VERSION ""

NS_ :

BS_:

BU_: FUSION IVI HMI Telltale

BO_ 535 FD_BCM2: 24 FUSION
 SG_ AmbLightBrightness1 : 190|7@0+ (1,0) [0|127] "" Vector__XXX
 SG_ AmbLightBrightness2 : 182|7@0+ (1,0) [0|127] "" Vector__XXX
 SG_ AmbLightBrightness3 : 174|7@0+ (1,0) [0|127] "" Vector__XXX
 SG_ AmbLightColor1 : 165|6@0+ (1,0) [0|63] "" Vector__XXX
 SG_ AmbLightColor2 : 157|6@0+ (1,0) [0|63] "" Vector__XXX
 SG_ AmbLightColor3 : 149|6@0+ (1,0) [0|63] "" Vector__XXX
 SG_ User1AmbLightColor : 141|6@0+ (1,0) [0|63] "" IVI
 SG_ User2AmbLightColor : 133|6@0+ (1,0) [0|63] "" IVI
 SG_ User3AmbLightColor : 125|6@0+ (1,0) [0|63] "" IVI
 SG_ User4AmbLightColor : 117|6@0+ (1,0) [0|63] "" IVI
 SG_ User5AmbLightColor : 109|6@0+ (1,0) [0|63] "" IVI
 SG_ User6AmbLightColor : 101|6@0+ (1,0) [0|63] "" IVI
 SG_ User1IPAmbLightBrightness : 94|7@0+ (1,0) [0|127] "" IVI
 SG_ User2IPAmbLightBrightness : 86|7@0+ (1,0) [0|127] "" IVI
 SG_ User3IPAmbLightBrightness : 78|7@0+ (1,0) [0|127] "" IVI
 SG_ User4IPAmbLightBrightness : 70|7@0+ (1,0) [0|127] "" IVI
 SG_ User5IPAmbLightBrightness : 62|7@0+ (1,0) [0|127] "" IVI
 SG_ User6IPAmbLightBrightness : 54|7@0+ (1,0) [0|127] "" IVI
 SG_ User1DrAmbLightBrightness : 46|7@0+ (1,0) [0|127] "" IVI
 SG_ User2DrAmbLightBrightness : 38|7@0+ (1,0) [0|127] "" IVI
 SG_ User3DrAmbLightBrightness : 30|7@0+ (1,0) [0|127] "" IVI
 SG_ LampPwr : 31|1@0+ (1,0) [0|1] "" Vector__XXX
 SG_ User4DrAmbLightBrightness : 22|7@0+ (1,0) [0|127] "" IVI
 SG_ AmbLightBreath1 : 23|1@0+ (1,0) [0|1] "" Vector__XXX
 SG_ User5DrAmbLightBrightness : 14|7@0+ (1,0) [0|127] "" IVI
 SG_ AmbLightBreath2 : 15|1@0+ (1,0) [0|1] "" Vector__XXX
 SG_ User6DrAmbLightBrightness : 6|7@0+ (1,0) [0|127] "" IVI
 SG_ AmbLightBreath3 : 7|1@0+ (1,0) [0|1] "" Vector__XXX

BO_ 547 GW_ZoneDR6: 24 FUSION
 SG_ FrntPTCBusLineHiV : 177|10@0+ (1,0) [0|1023] "V" Vector__XXX
 SG_ FrntPTCRiBusLineC : 175|8@0+ (0.1,0) [0|25.5] "A" Vector__XXX
 SG_ FrntPTCLeBusLineC : 167|8@0+ (0.1,0) [0|25.5] "A" Vector__XXX
 SG_ FrntPTCRearRiCoreT : 159|8@0+ (1,-40) [-40|215] "Deg^C" Vector__XXX
 SG_ FrntPTCRearRiActHeatPwr : 151|8@0+ (25,0) [0|6375] "W" IVI
 SG_ FrntPTCRearLeCoreT : 143|8@0+ (1,-40) [-40|215] "Deg^C" Vector__XXX
 SG_ FrntPTCRearLeActHeatPwr : 135|8@0+ (25,0) [0|6375] "W" IVI
 SG_ FrntPTCRearRiBusLineC : 127|8@0+ (0.1,0) [0|25.5] "A" Vector__XXX
 SG_ FrntPTCPCBT : 119|8@0+ (1,-40) [-40|215] "Deg^C" Vector__XXX
 SG_ FrntPTCRiIGBTT : 111|8@0+ (1,-40) [-40|215] "Deg^C" Vector__XXX
 SG_ FrntPTCLeIGBTT : 103|8@0+ (1,-40) [-40|215] "Deg^C" Vector__XXX
 SG_ FrntPTCRiActHeatPwr : 95|8@0+ (25,0) [0|6375] "W" IVI
 SG_ FrntPTCLeActHeatPwr : 87|8@0+ (25,0) [0|6375] "W" IVI
 SG_ FrntPTCRiCoreT : 79|8@0+ (1,-40) [-40|215] "Deg^C" Vector__XXX
 SG_ FrntPTCLeCoreT : 71|8@0+ (1,-40) [-40|215] "Deg^C" Vector__XXX
 SG_ FrntPTCRearLeBusLineC : 63|8@0+ (0.1,0) [0|25.5] "A" Vector__XXX
 SG_ FrntPTCRearLeIGBTShoCFlt : 50|1@0+ (1,0) [0|1] "" Vector__XXX
 SG_ FrntPTCRearRiIGBTShoCFlt : 51|1@0+ (1,0) [0|1] "" Vector__XXX
 SG_ FrntPTCRearRiOpentCircFlt : 52|1@0+ (1,0) [0|1] "" Vector__XXX
 SG_ FrntPTCRearRiOverAFlt : 53|1@0+ (1,0) [0|1] "" Vector__XXX
 SG_ FrntPTCRearLeCoreTSnsrFlt : 54|1@0+ (1,0) [0|1] "" Vector__XXX
 SG_ FrntPTCRearRiCoreTSnsrFlt : 55|1@0+ (1,0) [0|1] "" Vector__XXX
 SG_ FrntPTCRearLeCoreOverTFlt : 40|1@0+ (1,0) [0|1] "" Vector__XXX
 SG_ FrntPTCRearRiCoreOverTFlt : 41|1@0+ (1,0) [0|1] "" Vector__XXX
 SG_ FrntPTCRearLeOpentCircFlt : 42|1@0+ (1,0) [0|1] "" Vector__XXX
 SG_ FrntPTCRearLeOverAFlt : 43|1@0+ (1,0) [0|1] "" Vector__XXX
 SG_ FrntPTCSupplierCod : 47|4@0+ (1,0) [0|15] "" Vector__XXX
 SG_ FrntPTCHWVers : 39|8@0+ (1,0) [0|255] "" Vector__XXX
 SG_ FrntPTCSWVers : 31|8@0+ (1,0) [0|255] "" Vector__XXX
 SG_ FrntPTCRiIGBTOverTFlt : 16|1@0+ (1,0) [0|1] "" Vector__XXX
 SG_ FrntPTCLeIGBTOverTFlt : 17|1@0+ (1,0) [0|1] "" Vector__XXX
 SG_ FrntPTCRiIGBTTSnsrFlt : 18|1@0+ (1,0) [0|1] "" Vector__XXX
 SG_ FrntPTCLeIGBTTSnsrFlt : 19|1@0+ (1,0) [0|1] "" Vector__XXX
 SG_ FrntPTCComFlt : 20|1@0+ (1,0) [0|1] "" Vector__XXX
 SG_ FrntPTCPCBOverTFlt : 21|1@0+ (1,0) [0|1] "" Vector__XXX
 SG_ FrntPTCPCBTSnsrFlt : 22|1@0+ (1,0) [0|1] "" Vector__XXX
 SG_ FrntPTCRiOpentCircFlt : 23|1@0+ (1,0) [0|1] "" Vector__XXX
 SG_ FrntPTCLeOpentCircFlt : 8|1@0+ (1,0) [0|1] "" Vector__XXX
 SG_ FrntPTCRiIGBTShoCircFlt : 9|1@0+ (1,0) [0|1] "" Vector__XXX
 SG_ FrntPTCLeIGBTShoCircFlt : 10|1@0+ (1,0) [0|1] "" Vector__XXX
 SG_ FrntPTCRiCoreOverTFlt : 11|1@0+ (1,0) [0|1] "" Vector__XXX
 SG_ FrntPTCLeCoreOverTFlt : 12|1@0+ (1,0) [0|1] "" Vector__XXX
 SG_ FrntPTCRiCoreTSnsrFlt : 13|1@0+ (1,0) [0|1] "" Vector__XXX
 SG_ FrntPTCLeCoreTSnsrFlt : 14|1@0+ (1,0) [0|1] "" Vector__XXX
 SG_ FrntPTCRiOverAFlt : 15|1@0+ (1,0) [0|1] "" Vector__XXX
 SG_ FrntPTCLeOverAFlt : 0|1@0+ (1,0) [0|1] "" Vector__XXX
 SG_ FrntPTCHVOverUFlt : 1|1@0+ (1,0) [0|1] "" Vector__XXX
 SG_ FrntPTCHVUnderUFlt : 2|1@0+ (1,0) [0|1] "" Vector__XXX
 SG_ FrntPTCLVOverUFlt : 3|1@0+ (1,0) [0|1] "" Vector__XXX
 SG_ FrntPTCLVUnderUFlt : 4|1@0+ (1,0) [0|1] "" Vector__XXX
 SG_ FrntPTCFltSt : 6|2@0+ (1,0) [0|3] "" Vector__XXX
 SG_ FrntPTCSts : 7|1@0+ (1,0) [0|1] "" Vector__XXX

BO_ 550 GW_ZoneDR1: 16 FUSION
 SG_ CSW_SW_version : 87|16@0+ (0.01,0) [0|99.99] "" Vector__XXX
 SG_ CSW_HW_version : 71|16@0+ (0.01,0) [0|99.99] "" Vector__XXX
 SG_ DrLockSta : 56|1@0+ (1,0) [0|1] "" Vector__XXX
 SG_ PsLockSta : 57|1@0+ (1,0) [0|1] "" Vector__XXX
 SG_ RLLockSta : 58|1@0+ (1,0) [0|1] "" Vector__XXX
 SG_ RRLockSta : 59|1@0+ (1,0) [0|1] "" Vector__XXX
 SG_ AllLockSta : 60|1@0+ (1,0) [0|1] "" Vector__XXX
 SG_ MIRROR_FOLD_SW : 61|1@0+ (1,0) [0|1] "" Vector__XXX
 SG_ RWiperAS : 62|1@0+ (1,0) [0|1] "" Vector__XXX
 SG_ RWiperProtection : 63|1@0+ (1,0) [0|1] "" Vector__XXX
 SG_ Wip_Speed : 49|2@0+ (1,0) [0|3] "" Vector__XXX
 SG_ CSW_RWipIntSw_Sta : 51|2@0+ (1,0) [0|3] "" Vector__XXX
 SG_ CSW_DimSw : 52|1@0+ (1,0) [0|1] "" IVI
 SG_ BrakeLampFail : 53|1@0+ (1,0) [0|1] "" Vector__XXX
 SG_ CSW_PassSW_Sta : 54|1@0+ (1,0) [0|1] "" Vector__XXX
 SG_ RLS_Exist : 55|1@0+ (1,0) [0|1] "" Vector__XXX
 SG_ RLTurnLampC : 47|8@0+ (10,0) [0|2550] "mA" Vector__XXX
 SG_ RRTurnLampC : 39|8@0+ (10,0) [0|2550] "mA" Vector__XXX
 SG_ CSW_FWasSw_Sta : 25|2@0+ (1,0) [0|3] "" Vector__XXX
 SG_ CSW_RWasSW_Sta : 27|2@0+ (1,0) [0|3] "" Vector__XXX
 SG_ CSW_TurnSw_Sta : 29|2@0+ (1,0) [0|3] "" IVI
 SG_ HornSW : 30|1@0+ (1,0) [0|1] "" Vector__XXX
 SG_ CSW_FWipSw_Sta : 18|3@0+ (1,0) [0|7] "" IVI
 SG_ RLS_RainSnrWiperCmd : 22|3@0+ (1,0) [0|7] "" Vector__XXX
 SG_ RLS_Lamp_Sta : 23|1@0+ (1,0) [0|1] "" IVI
 SG_ WiperSWPos : 15|8@0+ (1,0) [0|255] "" Vector__XXX
 SG_ CSW_resp_error : 2|1@0+ (1,0) [0|1] "" Vector__XXX
 SG_ AutoLightSW : 3|1@0+ (1,0) [0|1] "" Vector__XXX
 SG_ WiperZeroPosSW : 4|1@0+ (1,0) [0|1] "" Vector__XXX
 SG_ RLS_RainSnrErr : 5|1@0+ (1,0) [0|1] "" Vector__XXX
 SG_ RLS_LightSnrErr : 6|1@0+ (1,0) [0|1] "" Vector__XXX
 SG_ RLS_LIN_Resp_Err : 7|1@0+ (1,0) [0|1] "" Vector__XXX

BO_ 552 GW_ZoneFR1: 20 FUSION
 SG_ CCV4_MoveEnable : 152|1@0+ (1,0) [0|1] "" Vector__XXX
 SG_ CCV4_ReqMovePos : 153|1@0+ (1,0) [0|1] "" Vector__XXX
 SG_ EWP1_Default_Operation_EWP_Rq : 154|1@0+ (1,0) [0|1] "" Vector__XXX
 SG_ EWP3_Default_Operation_EWP_Rq : 155|1@0+ (1,0) [0|1] "" Vector__XXX
 SG_ BDC_1_MoveEnable : 156|1@0+ (1,0) [0|1] "" Vector__XXX
 SG_ EWP2_Default_Operation_EWP_Rq : 157|1@0+ (1,0) [0|1] "" Vector__XXX
 SG_ EXV_Cmd_Move_Enbl : 158|1@0+ (1,0) [0|1] "" Vector__XXX
 SG_ EXV2_Cmd_Move_Enbl : 159|1@0+ (1,0) [0|1] "" Vector__XXX
 SG_ EXV2_Cmd_Init_Rq : 146|3@0+ (1,0) [0|1] "" Vector__XXX
 SG_ EXV_Cmd_Init_Rq : 149|3@0+ (1,0) [0|1] "" Vector__XXX
 SG_ EWP1_RPM_Target_EWP_Rq : 143|8@0+ (1,0) [0|254] "" Vector__XXX
 SG_ EWP3_RPM_Target_EWP_Rq : 135|8@0+ (1,0) [0|254] "" Vector__XXX
 SG_ BDC_1_ReqMovePos : 127|8@0+ (0.392,0) [0|99.96] "" Vector__XXX
 SG_ EWP2_RPM_Target_EWP_Rq : 119|8@0+ (1,0) [0|254] "" Vector__XXX
 SG_ EXV_Cmd_Set_Rq : 103|16@0+ (1,0) [0|576] "" Vector__XXX
 SG_ EXV2_Cmd_Set_Rq : 87|16@0+ (1,0) [0|576] "" Vector__XXX
 SG_ FWiperAS : 56|1@0+ (1,0) [0|1] "" Vector__XXX
 SG_ FWiperProtection : 57|1@0+ (1,0) [0|1] "" Vector__XXX
 SG_ ChargeInletLockSta : 58|1@0+ (1,0) [0|1] "" IVI
 SG_ FLTurnLampC : 55|8@0+ (10,0) [0|2550] "mA" Vector__XXX
 SG_ FRTurnLampC : 47|8@0+ (10,0) [0|2550] "mA" Vector__XXX
 SG_ AGS_Position_Request : 31|8@0+ (1,0) [0|255] "" Vector__XXX
 SG_ AGS_Calibration_Enabled : 22|1@0+ (1,0) [0|1] "" Vector__XXX
 SG_ AGS_LINResponse_Error : 23|1@0+ (1,0) [0|1] "" Vector__XXX
 SG_ AGS_Actuator_Blocked : 8|1@0+ (1,0) [0|1] "" Vector__XXX
 SG_ AGS_Actuator_Fault : 9|1@0+ (1,0) [0|1] "" Vector__XXX
 SG_ AGS_Calibration_Active : 10|1@0+ (1,0) [0|1] "" Vector__XXX
 SG_ AGS_Calibration_Indicated : 11|1@0+ (1,0) [0|1] "" Vector__XXX
 SG_ AGS_Electrical_Error : 12|1@0+ (1,0) [0|1] "" Vector__XXX
 SG_ AGS_Sensor_Error : 13|1@0+ (1,0) [0|1] "" Vector__XXX
 SG_ AGS_Temperature_Error : 14|1@0+ (1,0) [0|1] "" Vector__XXX
 SG_ AGS_Low_Voltage_Error : 15|1@0+ (1,0) [0|1] "" Vector__XXX
 SG_ AGS_Actual_Position : 7|8@0+ (1,0) [0|240] "" IVI

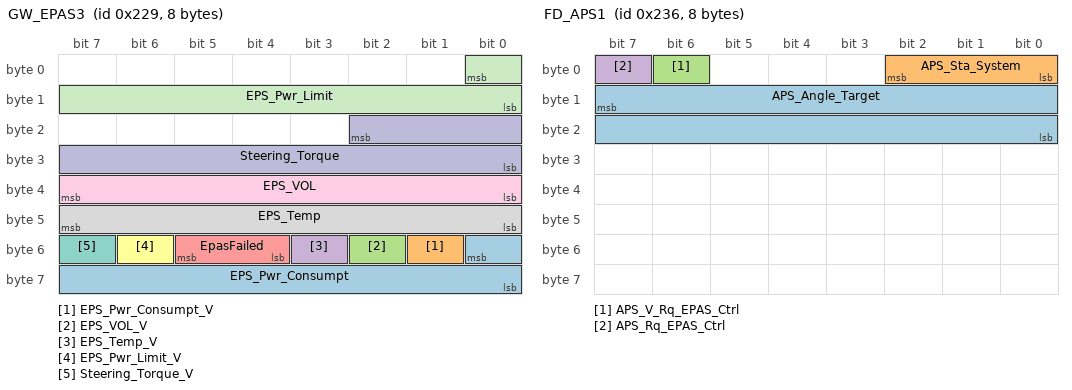
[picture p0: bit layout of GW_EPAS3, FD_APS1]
BO_ 553 GW_EPAS3: 8 FUSION
 SG_ EPS_Pwr_Consumpt : 48|9@0+ (0.5,0) [0|135] "A" Vector__XXX
 SG_ EPS_Pwr_Consumpt_V : 49|1@0+ (1,0) [0|1] "" Vector__XXX
 SG_ EPS_VOL_V : 50|1@0+ (1,0) [0|1] "" Vector__XXX
 SG_ EPS_Temp_V : 51|1@0+ (1,0) [0|1] "" Vector__XXX
 SG_ EpasFailed : 53|2@0+ (1,0) [0|2] "" IVI,Telltale
 SG_ EPS_Pwr_Limit_V : 54|1@0+ (1,0) [0|1] "" Vector__XXX
 SG_ Steering_Torque_V : 55|1@0+ (1,0) [0|1] "" Vector__XXX
 SG_ EPS_Temp : 47|8@0+ (1,-100) [-100|155] "Deg^C" Vector__XXX
 SG_ EPS_VOL : 39|8@0+ (0.1,0) [0|25.5] "V" Vector__XXX
 SG_ Steering_Torque : 18|11@0+ (0.01,-10) [-10|10] "Nm" Vector__XXX
 SG_ EPS_Pwr_Limit : 0|9@0+ (0.5,0) [0|135] "A" Vector__XXX

BO_ 566 FD_APS1: 8 FUSION
 SG_ APS_Angle_Target : 15|16@0+ (0.1,-900) [-900|900] "Deg" Vector__XXX
 SG_ APS_Sta_System : 2|3@0+ (1,0) [0|7] "" IVI
 SG_ APS_V_Rq_EPAS_Ctrl : 6|1@0+ (1,0) [0|1] "" Vector__XXX
 SG_ APS_Rq_EPAS_Ctrl : 7|1@0+ (1,0) [0|1] "" Vector__XXX

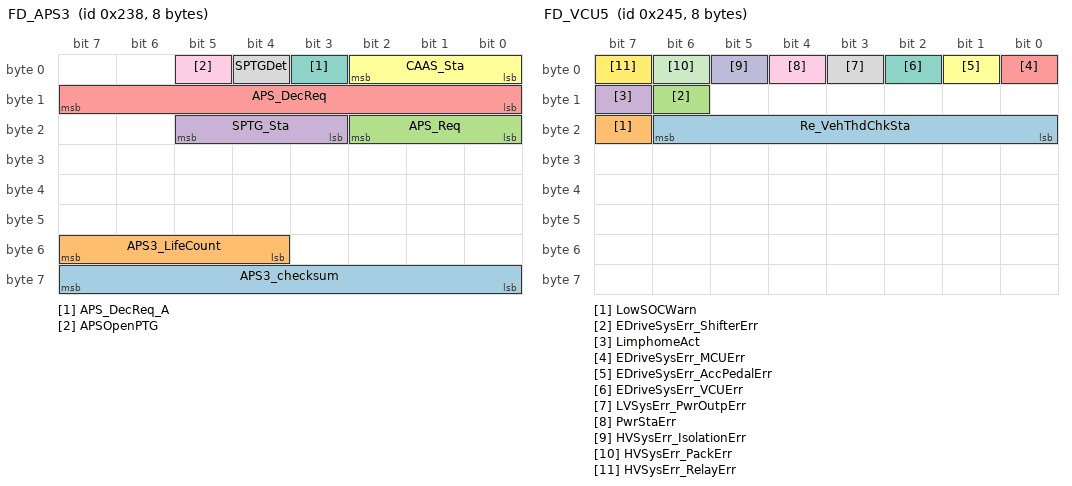
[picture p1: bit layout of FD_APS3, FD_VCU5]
BO_ 568 FD_APS3: 8 FUSION
 SG_ APS3_checksum : 63|8@0+ (1,0) [0|255] "" Vector__XXX
 SG_ APS3_LifeCount : 55|4@0+ (1,0) [0|15] "" Vector__XXX
 SG_ APS_Req : 18|3@0+ (1,0) [0|7] "" Vector__XXX
 SG_ SPTG_Sta : 21|3@0+ (1,0) [0|7] "" Vector__XXX
 SG_ APS_DecReq : 15|8@0+ (0.1,0) [0|25.4] "m/s^2" Vector__XXX
 SG_ CAAS_Sta : 2|3@0+ (1,0) [0|7] "" IVI
 SG_ APS_DecReq_A : 3|1@0+ (1,0) [0|1] "" Vector__XXX
 SG_ SPTGDet : 4|1@0+ (1,0) [0|1] "" Vector__XXX
 SG_ APSOpenPTG : 5|1@0+ (1,0) [0|1] "" Vector__XXX

BO_ 570 GW_FCM4: 8 FUSION
 SG_ FCM4_Checksum : 63|8@0+ (1,0) [0|255] "" IVI
 SG_ ADAS_SLIF_SpdLim : 52|5@0+ (1,0) [0|31] "" IVI
 SG_ Target_Type : 40|4@0+ (1,0) [0|15] "" IVI
 SG_ ADAS_CAM_SpdLim : 47|5@0+ (1,0) [0|31] "" IVI
 SG_ ADAS_WarningMsg : 35|4@0+ (1,0) [0|15] "" IVI
 SG_ ACC_TakeoverReq : 36|1@0+ (1,0) [0|1] "" IVI
 SG_ ACCSetSpeed_Disp : 39|3@0+ (1,0) [0|7] "" IVI
 SG_ ACCSetSpeed : 31|8@0+ (1,0) [0|254] "" IVI
 SG_ TimeGapLevel : 18|3@0+ (1,0) [0|7] "" IVI
 SG_ ForceLowBeam : 20|2@0+ (1,0) [0|1] "" IVI
 SG_ ACC_ObjDstLvl : 23|3@0+ (1,0) [0|7] "" IVI
 SG_ ADAS_ACC_Sta : 10|3@0+ (1,0) [0|7] "" IVI
 SG_ ADAS_FltWrnReq : 11|1@0+ (1,0) [0|1] "" IVI
 SG_ ADAS_LDW_Sta : 14|3@0+ (1,0) [0|7] "" IVI
 SG_ LeftTurnLightReq : 15|1@0+ (1,0) [0|1] "" IVI
 SG_ ADAS_FCW_Sta : 2|3@0+ (1,0) [0|7] "" IVI
 SG_ RightTurnLightReq : 3|1@0+ (1,0) [0|1] "" IVI
 SG_ ADAS_AEB_Sta : 6|3@0+ (1,0) [0|7] "" IVI
 SG_ HazardWarningReq : 7|1@0+ (1,0) [0|1] "" IVI

BO_ 572 GW_FCM5: 8 FUSION
 SG_ FCM5_Checksum : 63|8@0+ (1,0) [0|255] "" IVI
 SG_ ADAS_LFC_Warn_Sound : 55|8@0+ (1,0) [0|255] "" IVI
 SG_ LVDA_ACCStatusInformation : 40|1@0+ (1,0) [0|1] "" IVI
 SG_ LVDA_Warning : 41|1@0+ (1,0) [0|1] "" IVI
 SG_ LVDA_Failinfo : 42|1@0+ (1,0) [0|1] "" IVI
 SG_ LVDA_Mute_Sta : 44|2@0+ (1,0) [0|3] "" IVI
 SG_ LVDA_Disabled : 45|1@0+ (1,0) [0|1] "" IVI
 SG_ ADAS_LFC_Hands_Off_Warning : 47|2@0+ (1,0) [0|3] "" IVI
 SG_ ADAS_FCW_Mute : 32|1@0+ (1,0) [0|1] "" IVI
 SG_ ADAS_LDW_Mute : 34|1@0+ (1,0) [0|1] "" IVI
 SG_ ADAS_ISA_Sta : 36|2@0+ (1,0) [0|3] "" IVI
 SG_ ADAS_SLIF_Sta : 30|3@0+ (1,0) [0|5] "" IVI
 SG_ ADAS_LaneModeR : 22|3@0+ (1,0) [0|7] "" IVI
 SG_ ADAS_LaneModeL : 10|3@0+ (1,0) [0|7] "" IVI
 SG_ ADAS_LFC_Sta : 2|3@0+ (1,0) [0|7] "" IVI
 SG_ LKA_HOD_Sound_Warning : 3|1@0+ (1,0) [0|1] "" IVI
 SG_ ADAS_LKA_Sta : 6|3@0+ (1,0) [0|7] "" IVI
 SG_ LKA_HOD_Display_Warning : 7|1@0+ (1,0) [0|1] "" IVI

BO_ 581 FD_VCU5: 8 FUSION
 SG_ Re_VehThdChkSta : 22|7@0+ (1,0) [0|127] "" Vector__XXX
 SG_ LowSOCWarn : 23|1@0+ (1,0) [0|1] "" Vector__XXX
 SG_ EDriveSysErr_ShifterErr : 14|1@0+ (1,0) [0|1] "" IVI,Telltale
 SG_ LimphomeAct : 15|1@0+ (1,0) [0|1] "" IVI,Telltale
 SG_ EDriveSysErr_MCUErr : 0|1@0+ (1,0) [0|1] "" IVI,Telltale
 SG_ EDriveSysErr_AccPedalErr : 1|1@0+ (1,0) [0|1] "" IVI,Telltale
 SG_ EDriveSysErr_VCUErr : 2|1@0+ (1,0) [0|1] "" IVI,Telltale
 SG_ LVSysErr_PwrOutpErr : 3|1@0+ (1,0) [0|1] "" IVI,Telltale
 SG_ PwrStaErr : 4|1@0+ (1,0) [0|1] "" IVI,Telltale
 SG_ HVSysErr_IsolationErr : 5|1@0+ (1,0) [0|1] "" IVI,Telltale
 SG_ HVSysErr_PackErr : 6|1@0+ (1,0) [0|1] "" IVI,Telltale
 SG_ HVSysErr_RelayErr : 7|1@0+ (1,0) [0|1] "" IVI,Telltale

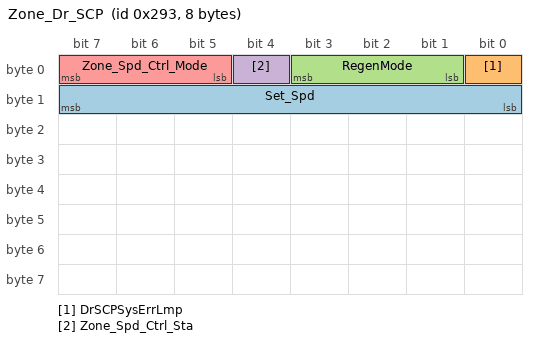
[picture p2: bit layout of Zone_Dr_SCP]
BO_ 659 Zone_Dr_SCP: 8 FUSION
 SG_ Set_Spd : 15|8@0+ (1,0) [0|255] "km/h" IVI
 SG_ DrSCPSysErrLmp : 0|1@0+ (1,0) [0|1] "" Telltale
 SG_ RegenMode : 3|3@0+ (1,0) [0|7] "" IVI
 SG_ Zone_Spd_Ctrl_Sta : 4|1@0+ (1,0) [0|1] "" IVI
 SG_ Zone_Spd_Ctrl_Mode : 7|3@0+ (1,0) [0|7] "" IVI

BO_ 809 GW_BMS3: 32 FUSION
 SG_ HVBattSOCDis : 255|8@0+ (0.4,0) [0|100] "%" IVI
 SG_ HVBattSOC : 247|8@0+ (0.4,0) [0|100] "%" IVI
 SG_ HVBattPackVolt : 228|13@0+ (0.1,0) [0|819] "V" Vector__XXX
 SG_ HVBChrgPwr : 223|10@0+ (0.1,0) [0|102.2] "KWh" IVI
 SG_ HVBDrvPwr : 199|10@0+ (0.1,0) [0|102.2] "KWh" Vector__XXX
 SG_ HVBFullChrgPwr : 177|10@0+ (0.1,0) [0|102.2] "KWh" Vector__XXX
 SG_ RemainChrgTime : 175|12@0+ (1,0) [0|4094] "MINUTE" IVI
 SG_ HVBSOH : 167|8@0+ (0.4,0) [0|100] "%" Vector__XXX
 SG_ HVBIsoImpedenceP : 150|15@0+ (0.01,0) [0|327.66] "Megaohm" Vector__XXX
 SG_ HVBIsoImpedenceN : 134|15@0+ (0.01,0) [0|327.66] "Megaohm" Vector__XXX
 SG_ Battsystfail_Num : 127|8@0+ (1,0) [0|253] "" Vector__XXX
 SG_ RechrgCyc : 97|18@0+ (1,0) [0|262142] "CYCLE" Vector__XXX
 SG_ CellType : 101|4@0+ (1,0) [0|7] "" Vector__XXX
 SG_ ACChrgCurrDis : 86|15@0+ (0.1,-1000) [-1000|2276.5] "A" IVI
 SG_ HVBChrgPwrTotal : 57|18@0+ (1,0) [0|262143] "KWh" Vector__XXX
 SG_ HVBDrvPwrTotal : 33|18@0+ (1,0) [0|262143] "KWh" Vector__XXX
 SG_ HVBattSOCDiff : 213|6@0+ (1,0) [0|63] "%" Vector__XXX
 SG_ SOC_UseLimit : 215|2@0+ (1,0) [0|3] "" Vector__XXX
 SG_ BMS_HVBattCellBalance_Sta : 200|1@0+ (1,0) [0|1] "" Vector__XXX

BO_ 820 GW_BMS8: 48 FUSION
 SG_ MainPosstandard : 279|16@0+ (1,0) [0|65535] "" Vector__XXX
 SG_ MainChrgRlyNegOutterVoltage : 263|16@0+ (1,0) [0|65535] "" Vector__XXX
 SG_ MainChrgRlyPosOutterVoltage : 247|16@0+ (1,0) [0|65535] "" Vector__XXX
 SG_ MainRlyNegOutterVoltage : 231|16@0+ (1,0) [0|65535] "" Vector__XXX
 SG_ G0standard : 215|16@0+ (1,0) [0|65535] "" Vector__XXX
 SG_ MainRlyPosOutterVoltage : 199|16@0+ (1,0) [0|65535] "" Vector__XXX
 SG_ MainRlyPosInnerVoltage : 183|16@0+ (1,0) [0|65535] "" Vector__XXX
 SG_ MainChrgRlyPosSta : 175|8@0+ (1,0) [0|255] "" Vector__XXX
 SG_ MainChrgRlyNegSta : 167|8@0+ (1,0) [0|255] "" Vector__XXX
 SG_ MainRlyNegSta : 159|8@0+ (1,0) [0|255] "" IVI
 SG_ MainRlyPosSta : 151|8@0+ (1,0) [0|255] "" IVI
 SG_ MainChrgRlyNegDriReq : 143|8@0+ (1,0) [0|255] "" Vector__XXX
 SG_ MainChrgRlyPosDriReq : 135|8@0+ (1,0) [0|255] "" Vector__XXX
 SG_ MainRlyNegDriReq : 127|8@0+ (1,0) [0|255] "" Vector__XXX
 SG_ MainRlyPosDriReq : 119|8@0+ (1,0) [0|255] "" Vector__XXX
 SG_ TherRunawayErrMask : 87|32@0+ (1,0) [0|4.294967295E9] "" Vector__XXX
 SG_ DCChrgCurrent : 55|32@0+ (0.01,-2000) [-2000|6000] "A" Vector__XXX
 SG_ DCChrgVoltage : 39|16@0+ (0.1,0) [0|6553.5] "V" Vector__XXX
 SG_ ACChrgStop : 31|8@0+ (1,0) [0|255] "" Vector__XXX
 SG_ DCChrgStop : 23|8@0+ (1,0) [0|255] "" Vector__XXX
 SG_ CurrentErrorID : 7|16@0+ (1,0) [0|65535] "" Vector__XXX

BO_ 826 GW_ZoneDR2: 8 FUSION
 SG_ SWC_LKA_Sta : 61|1@0+ (1,0) [0|1] "" IVI
 SG_ SWC_Undefined_Sta : 62|1@0+ (1,0) [0|1] "" IVI
 SG_ SWC_VR_Sta : 63|1@0+ (1,0) [0|1] "" IVI
 SG_ SWC_Up_Sta : 48|1@0+ (1,0) [0|1] "" IVI
 SG_ SWC_Trip_Sta : 50|1@0+ (1,0) [0|1] "" IVI
 SG_ SWC_Set_down_Sta : 51|1@0+ (1,0) [0|1] "" Vector__XXX
 SG_ SWC_Right_Sta : 52|1@0+ (1,0) [0|1] "" IVI
 SG_ SWC_RegenDown : 53|1@0+ (1,0) [0|1] "" Vector__XXX
 SG_ SWC_Res_Up_Sta : 54|1@0+ (1,0) [0|1] "" Vector__XXX
 SG_ SWC_resp_error : 55|1@0+ (1,0) [0|1] "" Vector__XXX
 SG_ SWC_mode_Sta : 43|1@0+ (1,0) [0|1] "" IVI
 SG_ SWC_Left_Sta : 45|1@0+ (1,0) [0|1] "" IVI
 SG_ SWC_RegenUp : 46|1@0+ (1,0) [0|1] "" IVI
 SG_ SWC_Down_Sta : 47|1@0+ (1,0) [0|1] "" IVI
 SG_ SWC_Distance_Sta : 32|1@0+ (1,0) [0|1] "" Vector__XXX
 SG_ SWC_A_Resp_Err : 34|1@0+ (1,0) [0|1] "" Vector__XXX
 SG_ SWC_ACC_Sta : 36|1@0+ (1,0) [0|1] "" IVI
 SG_ SWC_CANCEL_Sta : 37|1@0+ (1,0) [0|1] "" Vector__XXX
 SG_ SWC_Drivemode_Sta : 39|2@0+ (1,0) [0|1] "" Vector__XXX
 SG_ SWC_A_HW_version : 23|16@0+ (0.01,0) [0|99.99] "" Vector__XXX
 SG_ SWC_A_SW_version : 7|16@0+ (0.01,0) [0|99.99] "" Vector__XXX

BO_ 851 GW_ZoneDR4: 8 FUSION
 SG_ L_RLD_Wdw_Running_Sts : 58|3@0+ (1,0) [0|7] "" Vector__XXX
 SG_ L_RLD_Wdw_LocalSwitch : 61|3@0+ (1,0) [0|7] "" Vector__XXX
 SG_ L_RLD_Wdw_PositionSts : 63|2@0+ (1,0) [0|3] "" Vector__XXX
 SG_ L_RLD_Val_Wdw_Opened : 54|7@0+ (1,0) [0|100] "%" IVI
 SG_ L_RLD_Motor_Ripple_Error : 55|1@0+ (1,0) [0|1] "" Vector__XXX
 SG_ L_RLD_Motor_Relay_Error : 40|1@0+ (1,0) [0|1] "" Vector__XXX
 SG_ L_RLD_OverHeat_Protect : 41|1@0+ (1,0) [0|1] "" Vector__XXX
 SG_ L_RLD_Wdw_Init : 42|1@0+ (1,0) [0|1] "" Vector__XXX
 SG_ L_RLD_Wdw_OD_Sts : 43|1@0+ (1,0) [0|1] "" Vector__XXX
 SG_ L_RLD_Wdw_Obs_InhibitSts : 44|1@0+ (1,0) [0|1] "" Vector__XXX
 SG_ RAPWL_01_LIN_Response_Error : 45|1@0+ (1,0) [0|1] "" Vector__XXX
 SG_ L_RRD_Wdw_Running_Sts : 34|3@0+ (1,0) [0|7] "" Vector__XXX
 SG_ L_RRD_Wdw_LocalSwitch : 37|3@0+ (1,0) [0|7] "" Vector__XXX
 SG_ L_RRD_Wdw_PositionSts : 39|2@0+ (1,0) [0|3] "" Vector__XXX
 SG_ L_RRD_Val_Wdw_Opened : 30|7@0+ (1,0) [0|100] "%" IVI
 SG_ L_RRD_Motor_Ripple_Error : 31|1@0+ (1,0) [0|1] "" Vector__XXX
 SG_ L_RRD_Motor_Relay_Error : 16|1@0+ (1,0) [0|1] "" Vector__XXX
 SG_ L_RRD_OverHeat_Protect : 17|1@0+ (1,0) [0|1] "" Vector__XXX
 SG_ L_RRD_Wdw_Init : 18|1@0+ (1,0) [0|1] "" Vector__XXX
 SG_ L_RRD_Wdw_OD_Sts : 19|1@0+ (1,0) [0|1] "" Vector__XXX
 SG_ L_RRD_Wdw_Obs_InhibitSts : 20|1@0+ (1,0) [0|1] "" Vector__XXX
 SG_ PTG_Inner_SW_2 : 47|2@0+ (1,0) [0|3] "" Vector__XXX

BO_ 854 GW_ZoneDR3: 8 FUSION
 SG_ L_Drv_Wdw_Running_Sts : 58|3@0+ (1,0) [0|7] "" Vector__XXX
 SG_ L_Drv_Wdw_LocalSwitch : 61|3@0+ (1,0) [0|7] "" Vector__XXX
 SG_ L_Drv_Wdw_PositionSts : 63|2@0+ (1,0) [0|3] "" Vector__XXX
 SG_ L_Drv_Val_Wdw_Opened : 54|7@0+ (1,0) [0|100] "%" IVI
 SG_ L_Drv_Motor_Ripple_Error : 55|1@0+ (1,0) [0|1] "" Vector__XXX
 SG_ L_Drv_Motor_Relay_Error : 40|1@0+ (1,0) [0|1] "" Vector__XXX
 SG_ L_Drv_OverHeat_Protect : 41|1@0+ (1,0) [0|1] "" Vector__XXX
 SG_ L_Drv_Wdw_Init : 42|1@0+ (1,0) [0|1] "" Vector__XXX
 SG_ L_Drv_Wdw_OD_Sts : 43|1@0+ (1,0) [0|1] "" Vector__XXX
 SG_ L_Drv_Wdw_Obs_InhibitSts : 44|1@0+ (1,0) [0|1] "" Vector__XXX
 SG_ FAPWL_01_LIN_Response_Error : 45|1@0+ (1,0) [0|1] "" Vector__XXX
 SG_ L_Power_Status : 47|2@0+ (1,0) [0|3] "" Vector__XXX
 SG_ L_Pas_Wdw_Running_Sts : 34|3@0+ (1,0) [0|7] "" Vector__XXX
 SG_ L_Pas_Wdw_LocalSwitch : 37|3@0+ (1,0) [0|7] "" Vector__XXX
 SG_ L_Pas_Wdw_PositionSts : 39|2@0+ (1,0) [0|3] "" Vector__XXX
 SG_ L_Pas_Val_Wdw_Opened : 31|7@0+ (1,0) [0|100] "%" IVI
 SG_ L_Pas_Motor_Ripple_Error : 16|1@0+ (1,0) [0|1] "" Vector__XXX
 SG_ L_Pas_Motor_Relay_Error : 17|1@0+ (1,0) [0|1] "" Vector__XXX
 SG_ L_Pas_OverHeat_Protect : 18|1@0+ (1,0) [0|1] "" Vector__XXX
 SG_ L_Pas_Wdw_Init : 19|1@0+ (1,0) [0|1] "" Vector__XXX
 SG_ L_Pas_Wdw_OD_Sts : 20|1@0+ (1,0) [0|1] "" Vector__XXX
 SG_ L_Pas_Wdw_Obs_InhibitSts : 21|1@0+ (1,0) [0|1] "" Vector__XXX
 SG_ L_Drv_Wdw_Pas_Switch : 11|3@0+ (1,0) [0|7] "" Vector__XXX
 SG_ L_Drv_Wdw_RLD_Switch : 14|3@0+ (1,0) [0|7] "" Vector__XXX
 SG_ L_Drv_Wdw_RRD_Switch : 1|3@0+ (1,0) [0|7] "" Vector__XXX
 SG_ L_APM_IntellectClose : 7|1@0+ (1,0) [0|1] "" Vector__XXX

CM_ SG_ 535 AmbLightBrightness1 "Atmosphere Lamp 1 Bright adjustment";
CM_ SG_ 535 AmbLightBrightness2 "Atmosphere Lamp 2 Bright adjustment";
CM_ SG_ 535 AmbLightBrightness3 "Atmosphere Lamp 3 Bright adjustment";
CM_ SG_ 535 AmbLightColor1 "RGB 64 Color";
CM_ SG_ 535 AmbLightColor2 "RGB 64 Color";
CM_ SG_ 535 AmbLightColor3 "RGB 64 Color";
CM_ SG_ 535 User1AmbLightColor "Atmosphere Lamp User 1 Color";
CM_ SG_ 535 User2AmbLightColor "Atmosphere Lamp User 2 Color";
CM_ SG_ 535 User3AmbLightColor "Atmosphere Lamp User 3 Color";
CM_ SG_ 535 User4AmbLightColor "Atmosphere Lamp User 4 Color";
CM_ SG_ 535 User5AmbLightColor "Atmosphere Lamp User 5 Color";
CM_ SG_ 535 User6AmbLightColor "Atmosphere Lamp User 6 Color";
CM_ SG_ 535 User1IPAmbLightBrightness "Atmosphere Lamp User 1 IP Illumination";
CM_ SG_ 535 User2IPAmbLightBrightness "Atmosphere Lamp User 2 IP Illumination";
CM_ SG_ 535 User3IPAmbLightBrightness "Atmosphere Lamp User 3 IP Illumination";
CM_ SG_ 535 User4IPAmbLightBrightness "Atmosphere Lamp User 4 IP Illumination";
CM_ SG_ 535 User5IPAmbLightBrightness "Atmosphere Lamp User 5 IP Illumination";
CM_ SG_ 535 User6IPAmbLightBrightness "Atmosphere Lamp User 6 IP Illumination";
CM_ SG_ 535 User1DrAmbLightBrightness "Atmosphere Lamp User 1 Dr Illumination";
CM_ SG_ 535 User2DrAmbLightBrightness "Atmosphere Lamp User 2 Dr Illumination";
CM_ SG_ 535 User3DrAmbLightBrightness "Atmosphere Lamp User 3 Dr Illumination";
CM_ SG_ 535 LampPwr "Lamp Power";
CM_ SG_ 535 User4DrAmbLightBrightness "Atmosphere Lamp User 4 Dr Illumination";
CM_ SG_ 535 AmbLightBreath1 "Atmosphere Lamp 1 Breathing Mode";
CM_ SG_ 535 User5DrAmbLightBrightness "Atmosphere Lamp User 5 Dr Illumination";
CM_ SG_ 535 AmbLightBreath2 "Atmosphere Lamp 2 Breathing Mode";
CM_ SG_ 535 User6DrAmbLightBrightness "Atmosphere Lamp User 6 Dr Illumination";
CM_ SG_ 535 AmbLightBreath3 "Atmosphere Lamp 3 Breathing Mode";
CM_ SG_ 547 FrntPTCRearRiCoreT "Frnt PTC Rear Right Core Temperature
0x00~0xFE:Value
0xFF:Invalid";
CM_ SG_ 547 FrntPTCRearLeCoreT "0x00~0xFE:Value
0xFF:Invalid";
CM_ SG_ 547 FrntPTCRearLeActHeatPwr "Frnt PTC Rear Left Actual Heat Power
0x00-0xC8:actual value;
0xC9-0xFE:Reserved
0xFF:Invalid";
CM_ SG_ 547 FrntPTCRearRiBusLineC "Frnt PTC Rear Right  current
0xFF:Invalid";
CM_ SG_ 547 FrntPTCPCBT "Front PTC PCB Temperature";
CM_ SG_ 547 FrntPTCRiIGBTT "Front PTC Right IGBT Temperature";
CM_ SG_ 547 FrntPTCLeIGBTT "Front PTC Left IGBT Temperature";
CM_ SG_ 547 FrntPTCRiActHeatPwr "Front PTC Right Actual Heat Power";
CM_ SG_ 547 FrntPTCLeActHeatPwr "Front PTC Left Actual Heat Power";
CM_ SG_ 547 FrntPTCRiCoreT "Front PTC Right Core Temperature";
CM_ SG_ 547 FrntPTCLeCoreT "Front PTC Left Core Temperature";
CM_ SG_ 547 FrntPTCRearLeBusLineC "Frnt PTC Rear Left  current
0xFF:Invalid";
CM_ SG_ 547 FrntPTCRearLeIGBTShoCFlt "Frnt PTC Rear Left IGBT Short Circuit Fault";
CM_ SG_ 547 FrntPTCRearRiIGBTShoCFlt "Frnt PTC Rear Right IGBT Short Circuit Fault";
CM_ SG_ 547 FrntPTCRearRiOpentCircFlt "Frnt PTC Rear Right Opent Circuit Fault";
CM_ SG_ 547 FrntPTCRearRiOverAFlt "Frnt PTC Rear Right Over Current Fault";
CM_ SG_ 547 FrntPTCRearLeCoreTSnsrFlt "Frnt PTC Rear Left Core Temperature Sensor Fault";
CM_ SG_ 547 FrntPTCRearRiCoreTSnsrFlt "Frotn PTC Rear Right Core Temperature Sensor Fault";
CM_ SG_ 547 FrntPTCRearLeCoreOverTFlt "Frnt PTC Rear Left Core Over Remperature Fault";
CM_ SG_ 547 FrntPTCRearRiCoreOverTFlt "Frnt PTC Rear Right Core Over Remperature Fault";
CM_ SG_ 547 FrntPTCRearLeOpentCircFlt "Frnt PTC Rear Left Opent Circuit Fault";
CM_ SG_ 547 FrntPTCRearLeOverAFlt "Frnt PTC Rear Left Over Current Fault";
CM_ SG_ 547 FrntPTCSupplierCod "Front PTC Supplier Code";
CM_ SG_ 547 FrntPTCHWVers "Front PTC Hardware Version";
CM_ SG_ 547 FrntPTCSWVers "Front PTC Software Version";
CM_ SG_ 547 FrntPTCRiIGBTOverTFlt "Front PTC Right IGBT Over Temperature Fault";
CM_ SG_ 547 FrntPTCLeIGBTOverTFlt "Front PTC Left IGBT Over Temperature Fault";
CM_ SG_ 547 FrntPTCRiIGBTTSnsrFlt "Front PTC Right IGBT Temperature Sensor Fault";
CM_ SG_ 547 FrntPTCLeIGBTTSnsrFlt "Front PTC Left IGBT Temperature Sensor Fault";
CM_ SG_ 547 FrntPTCComFlt "Front PTC Communication Fault";
CM_ SG_ 547 FrntPTCPCBOverTFlt "Front PTC PCB Over Temperature Fault";
CM_ SG_ 547 FrntPTCPCBTSnsrFlt "Front PTC PCB Temperature Sensor Fault";
CM_ SG_ 547 FrntPTCRiOpentCircFlt "Front PTC Right Opent Circuit Fault";
CM_ SG_ 547 FrntPTCLeOpentCircFlt "Front PTC Left Opent Circuit Fault";
CM_ SG_ 547 FrntPTCRiIGBTShoCircFlt "Front PTC Right IGBT Short Circuit Fault";
CM_ SG_ 547 FrntPTCLeIGBTShoCircFlt "Front PTC Left IGBT Short Circuit Fault";
CM_ SG_ 547 FrntPTCRiCoreOverTFlt "Front PTC Right Core Over Remperature Fault";
CM_ SG_ 547 FrntPTCLeCoreOverTFlt "Front PTC Left Core Over Remperature Fault";
CM_ SG_ 547 FrntPTCRiCoreTSnsrFlt "Frotn PTC Right Core Temperature Sensor Fault";
CM_ SG_ 547 FrntPTCLeCoreTSnsrFlt "Front PTC Left Core Temperature Sensor Fault";
CM_ SG_ 547 FrntPTCRiOverAFlt "Front PTC Right Over Current Fault";
CM_ SG_ 547 FrntPTCLeOverAFlt "Front PTC Left Over Current Fault";
CM_ SG_ 547 FrntPTCHVOverUFlt "Frot PTC High Voltage Over Voltage Fault";
CM_ SG_ 547 FrntPTCHVUnderUFlt "Front PTC High Voltage Under Voltage Fault";
CM_ SG_ 547 FrntPTCLVOverUFlt "Front PTC Low Voltage Over Voltage Fault";
CM_ SG_ 547 FrntPTCLVUnderUFlt "Front PTC Low Voltage Under Voltage Fault";
CM_ SG_ 547 FrntPTCFltSt "Front PTC Fault Status";
CM_ SG_ 547 FrntPTCSts "Front PTC Status signals";
CM_ SG_ 550 DrLockSta "Driver Side Door Lock Staus";
CM_ SG_ 550 PsLockSta "Passenger Side Door Lock Status";
CM_ SG_ 550 RLLockSta "Rear Left Door Lock Status";
CM_ SG_ 550 RRLockSta "Rear Right Door Lock Status";
CM_ SG_ 550 AllLockSta "All Door Lock";
CM_ SG_ 550 MIRROR_FOLD_SW "MIRROR_FOLD_SW";
CM_ SG_ 550 RWiperAS "Rear Wiper AS";
CM_ SG_ 550 RWiperProtection "Rear Wiper Protection";
CM_ SG_ 550 Wip_Speed "Wip_Speed";
CM_ SG_ 550 CSW_RWipIntSw_Sta "CSW_RWipSW_Sta";
CM_ SG_ 550 CSW_DimSw "CSW_DimSw";
CM_ SG_ 550 BrakeLampFail "BrakeLamp Failed";
CM_ SG_ 550 CSW_PassSW_Sta "CSW_PassSW_Sta";
CM_ SG_ 550 RLS_Exist "RLS_Exist";
CM_ SG_ 550 RLTurnLampC "Rear Left TurnLamp Current";
CM_ SG_ 550 RRTurnLampC "Rear Right TurnLamp Current";
CM_ SG_ 550 CSW_FWasSw_Sta "CSW_FWasherSW_Sta";
CM_ SG_ 550 CSW_RWasSW_Sta "CSW_RWasherSW_Sta";
CM_ SG_ 550 CSW_TurnSw_Sta "CSW_TurnSw_Sta_CANbus";
CM_ SG_ 550 HornSW "Horn Switch status";
CM_ SG_ 550 RLS_RainSnrWiperCmd "RainSensorWiperCommand";
CM_ SG_ 550 RLS_Lamp_Sta "Lampstatus";
CM_ SG_ 550 WiperSWPos "WiperSwitchPosition";
CM_ SG_ 550 AutoLightSW "LightActivation";
CM_ SG_ 550 WiperZeroPosSW "WiperZeroPositionSwitch";
CM_ SG_ 550 RLS_RainSnrErr "RainSensorError";
CM_ SG_ 550 RLS_LightSnrErr "LightSensorError";
CM_ SG_ 552 FWiperAS "Front Wiper Auto Stop";
CM_ SG_ 552 FWiperProtection "Front Wiper Protection";
CM_ SG_ 552 ChargeInletLockSta "Charge Inlet lock signal status";
CM_ SG_ 552 FLTurnLampC "Front Left TurnLamp Current";
CM_ SG_ 552 FRTurnLampC "Front Right TurnLamp Current";
CM_ SG_ 552 AGS_Position_Request "AGS Position Request from Zone FR to AGS";
CM_ SG_ 552 AGS_Calibration_Enabled "Command for start calibration sequence (rising edge)";
CM_ SG_ 552 AGS_LINResponse_Error "Feedback of Response error bit";
CM_ SG_ 552 AGS_Actuator_Blocked "Feedback of Shutter blocked";
CM_ SG_ 552 AGS_Actuator_Fault "Feedback of Shutter actuator fault";
CM_ SG_ 552 AGS_Calibration_Active "Feedback of  Shutter calibration active";
CM_ SG_ 552 AGS_Calibration_Indicated "Feedback of Shutter calibration indicated";
CM_ SG_ 552 AGS_Electrical_Error "Feedback of electrical error";
CM_ SG_ 552 AGS_Sensor_Error "Feedback of Shutter position sensor fault";
CM_ SG_ 552 AGS_Temperature_Error "Feedback for overtemprature error";
CM_ SG_ 552 AGS_Low_Voltage_Error "Feedback for over/under voltage error";
CM_ SG_ 552 AGS_Actual_Position "Position feedback from the actuator";
CM_ SG_ 553 EPS_Pwr_Consumpt "EPS Power Consumption";
CM_ SG_ 553 EPS_Pwr_Consumpt_V "EPS Power Consumption Validity";
CM_ SG_ 553 EPS_VOL_V "EPS Voltage Validity";
CM_ SG_ 553 EPS_Temp_V "EPS Temperature Validity";
CM_ SG_ 553 EpasFailed "Epas Failed";
CM_ SG_ 553 EPS_Pwr_Limit_V "EPS Power Limit Validity";
CM_ SG_ 553 Steering_Torque_V "Steering Torque Validity";
CM_ SG_ 553 EPS_Temp "EPS Temperature";
CM_ SG_ 553 EPS_VOL "EPS Voltage";
CM_ SG_ 553 Steering_Torque "Steering Torque(Positive value is clockwise.)";
CM_ SG_ 553 EPS_Pwr_Limit "EPS Power Limit";
CM_ SG_ 566 APS_Angle_Target "to indicate the target steering angle(Positive value is clockwise.
When not being calibrated, invalid = 'FFFFh')";
CM_ SG_ 566 APS_Sta_System "The operation status of APA system";
CM_ SG_ 566 APS_V_Rq_EPAS_Ctrl "to indicate if the signal Request Active is valid or not";
CM_ SG_ 566 APS_Rq_EPAS_Ctrl "This signal is used when the APA need to control the steering wheel";
CM_ SG_ 568 APS3_checksum "checksum of APS3 (SAE-J1850-CRC8)
The [CAN CheckSum] shall be calculated as a CRC8 with the following polynomial: x^8+x^4+x^3+x^2+1 (=0x1D), according with SAE-J1850-CRC8 Start value 0xFF";
CM_ SG_ 568 APS3_LifeCount "Rolling counter of APS3";
CM_ SG_ 568 APS_Req "ESC control request";
CM_ SG_ 568 SPTG_Sta "The operation status of SPTG";
CM_ SG_ 568 APS_DecReq "APS Vehicle Deceleration Request";
CM_ SG_ 568 CAAS_Sta "The operation status of CAAS";
CM_ SG_ 568 APS_DecReq_A "APS Vehicle Deceleration Request Applicable";
CM_ SG_ 568 SPTGDet "Smart PTG Detecting";
CM_ SG_ 568 APSOpenPTG "Smart PTG open request";
CM_ SG_ 570 FCM4_Checksum "The [CAN CheckSum] shall be calculated as a CRC8 with the following polynomial: x^8+x^4+x^3+x^2+1 (=0x1D), according with SAE-J1850-CRC8 Start value 0xFF";
CM_ SG_ 570 ADAS_SLIF_SpdLim "ADAS SLIF Speed Limitation";
CM_ SG_ 570 Target_Type "Target Type";
CM_ SG_ 570 ADAS_CAM_SpdLim "ADAS Camera Speed Limitation";
CM_ SG_ 570 ADAS_WarningMsg "ADAS Warning Message";
CM_ SG_ 570 ACC_TakeoverReq "ACC takeover request";
CM_ SG_ 570 ACCSetSpeed_Disp "ACC Set Speed Display";
CM_ SG_ 570 ACCSetSpeed "ACC Set Speed(if Distance_unit = 0x0, then UNIT = km/h, else  UNIT = mph)";
CM_ SG_ 570 TimeGapLevel "Time Gap Level";
CM_ SG_ 570 ForceLowBeam "Force Low Beam";
CM_ SG_ 570 ACC_ObjDstLvl "Object distance level (lvl.1 ~ lvl.4)";
CM_ SG_ 570 ADAS_ACC_Sta "ACC Status";
CM_ SG_ 570 ADAS_FltWrnReq "ADAS Fault Warning Request";
CM_ SG_ 570 ADAS_LDW_Sta "LDW Status";
CM_ SG_ 570 LeftTurnLightReq "Left Turning Light Request";
CM_ SG_ 570 ADAS_FCW_Sta "FCW Status";
CM_ SG_ 570 RightTurnLightReq "Right Turning Light Request";
CM_ SG_ 570 ADAS_AEB_Sta "AEB Status";
CM_ SG_ 570 HazardWarningReq "Hazard Warning Request";
CM_ SG_ 572 FCM5_Checksum "The [CAN CheckSum] shall be calculated as a CRC8 with the following polynomial: x^8+x^4+x^3+x^2+1 (=0x1D), according with SAE-J1850-CRC8 Start value 0xFF";
CM_ SG_ 572 ADAS_LFC_Warn_Sound "LFC Warning Sound";
CM_ SG_ 572 LVDA_ACCStatusInformation "ACC status information for LVDA";
CM_ SG_ 572 LVDA_Warning "LVDA Warning";
CM_ SG_ 572 LVDA_Failinfo "LVDA Failinfo";
CM_ SG_ 572 LVDA_Mute_Sta "LVDA USM Setting";
CM_ SG_ 572 LVDA_Disabled "LVDA_Disabled";
CM_ SG_ 572 ADAS_LFC_Hands_Off_Warning "LFC Hands-Off Warning";
CM_ SG_ 572 ADAS_FCW_Mute "FCW Mute Status";
CM_ SG_ 572 ADAS_LDW_Mute "LDW Mute Status";
CM_ SG_ 572 ADAS_ISA_Sta "ISA Status";
CM_ SG_ 572 ADAS_SLIF_Sta "SLIF Status";
CM_ SG_ 572 ADAS_LaneModeR "Right Lane Mode";
CM_ SG_ 572 ADAS_LaneModeL "Left Lane Mode";
CM_ SG_ 572 ADAS_LFC_Sta "LFC Status";
CM_ SG_ 572 LKA_HOD_Sound_Warning "LKA hands-off detection sound warning signal";
CM_ SG_ 572 ADAS_LKA_Sta "LKA Status";
CM_ SG_ 572 LKA_HOD_Display_Warning "LKA hands-off detection display warning signal";
CM_ SG_ 581 Re_VehThdChkSta "Remote control for vehicle threshold check state";
CM_ SG_ 581 LowSOCWarn "AC Mode low SOC wanning";
CM_ SG_ 581 EDriveSysErr_ShifterErr "EDrive system Shifter error";
CM_ SG_ 581 LimphomeAct "Limp-home mode active";
CM_ SG_ 581 EDriveSysErr_MCUErr "EDrive system MCU error";
CM_ SG_ 581 EDriveSysErr_AccPedalErr "EDrive system acceleration pedal error";
CM_ SG_ 581 EDriveSysErr_VCUErr "EDrive system Fusion VCU error";
CM_ SG_ 581 LVSysErr_PwrOutpErr "LV power output error";
CM_ SG_ 581 PwrStaErr "Power state error";
CM_ SG_ 581 HVSysErr_IsolationErr "HV isolation error";
CM_ SG_ 581 HVSysErr_PackErr "HV battery pack error";
CM_ SG_ 581 HVSysErr_RelayErr "HV battery relay error";
CM_ SG_ 659 Set_Spd "speed setting under speed control function";
CM_ SG_ 659 DrSCPSysErrLmp "SCP system error lamp  request ";
CM_ SG_ 659 RegenMode "Regen Mode";
CM_ SG_ 659 Zone_Spd_Ctrl_Sta "Speed Control Function Status";
CM_ SG_ 659 Zone_Spd_Ctrl_Mode "Speed Control Function Mode";
CM_ SG_ 809 HVBattSOCDis "HV battery pack Display SOC";
CM_ SG_ 809 HVBattSOC "HV battery pack SOC";
CM_ SG_ 809 HVBattPackVolt "BMS pack voltage";
CM_ SG_ 809 HVBChrgPwr "Total Charge kWh";
CM_ SG_ 809 HVBDrvPwr "Total drive kWh";
CM_ SG_ 809 HVBFullChrgPwr "Full charge energy";
CM_ SG_ 809 RemainChrgTime "Remaining charge time";
CM_ SG_ 809 HVBSOH "Battery SOH";
CM_ SG_ 809 HVBIsoImpedenceP "Isolated Impedance BP";
CM_ SG_ 809 HVBIsoImpedenceN "Isolated Impedance BN";
CM_ SG_ 809 Battsystfail_Num "Number of failures of rechargeable energy storage device";
CM_ SG_ 809 RechrgCyc "Charge Cycles";
CM_ SG_ 809 CellType "HVB Cell Type";
CM_ SG_ 809 ACChrgCurrDis "HVB AC charge current max display";
CM_ SG_ 809 HVBChrgPwrTotal "Total Charge kWh accumulation";
CM_ SG_ 809 HVBDrvPwrTotal "Total Discharge kWh accumulation";
CM_ SG_ 809 HVBattSOCDiff "Difference from Cell SOCMax to Cell SOCMin";
CM_ SG_ 809 SOC_UseLimit "SOC Use Limit";
CM_ SG_ 809 BMS_HVBattCellBalance_Sta "Battery Cell Balance Flag";
CM_ SG_ 820 MainPosstandard "MainPosstandard";
CM_ SG_ 820 MainChrgRlyNegOutterVoltage "MainChrgRlyNegOutterVoltage";
CM_ SG_ 820 MainChrgRlyPosOutterVoltage "MainChrgRlyPosOutterVoltage";
CM_ SG_ 820 MainRlyNegOutterVoltage "MainRlyNegOutterVoltage";
CM_ SG_ 820 G0standard "G0standard";
CM_ SG_ 820 MainRlyPosOutterVoltage "MainRlyPosOutterVoltage";
CM_ SG_ 820 MainRlyPosInnerVoltage "MainRlyPosInnerVoltage";
CM_ SG_ 820 MainChrgRlyPosSta "MainChrgRlyPosSta";
CM_ SG_ 820 MainChrgRlyNegSta "MainChrgRlyNegSta";
CM_ SG_ 820 MainRlyNegSta "MainRlyNegSta";
CM_ SG_ 820 MainRlyPosSta "MainRlyPosSta";
CM_ SG_ 820 MainChrgRlyNegDriReq "MainChrgRlyNegDriReq";
CM_ SG_ 820 MainChrgRlyPosDriReq "MainChrgRlyPosDriReq";
CM_ SG_ 820 MainRlyNegDriReq "MainRlyNegDriReq";
CM_ SG_ 820 MainRlyPosDriReq "MainRlyPosDriReq";
CM_ SG_ 820 TherRunawayErrMask "ThermalRunawayErrorMask";
CM_ SG_ 820 DCChrgCurrent "DCChargeCurrent";
CM_ SG_ 820 DCChrgVoltage "DCChargeVoltage";
CM_ SG_ 820 ACChrgStop "ACChargeStop";
CM_ SG_ 820 DCChrgStop "DCChargeStop";
CM_ SG_ 820 CurrentErrorID "Current Error ID NO.";
CM_ SG_ 826 SWC_LKA_Sta "LKA Button Status";
CM_ SG_ 826 SWC_Undefined_Sta "Undefined button Status";
CM_ SG_ 826 SWC_VR_Sta "VR Button Status";
CM_ SG_ 826 SWC_Up_Sta "UP Button Status";
CM_ SG_ 826 SWC_Trip_Sta "Trip Button Status";
CM_ SG_ 826 SWC_Set_down_Sta "SET down Button Status";
CM_ SG_ 826 SWC_Right_Sta "Seek Forward track/radio";
CM_ SG_ 826 SWC_RegenDown "Regen Down";
CM_ SG_ 826 SWC_Res_Up_Sta "Res up Button Status";
CM_ SG_ 826 SWC_mode_Sta "Mode Button Status";
CM_ SG_ 826 SWC_Left_Sta "Seek Backward track/radio";
CM_ SG_ 826 SWC_RegenUp "Regen Up";
CM_ SG_ 826 SWC_Down_Sta "DOWN Button Status";
CM_ SG_ 826 SWC_Distance_Sta "Distance Button Status";
CM_ SG_ 826 SWC_ACC_Sta "ACC Button Status";
CM_ SG_ 826 SWC_CANCEL_Sta "CANCEL Button Status";
CM_ SG_ 851 L_RLD_Wdw_Running_Sts "Running status of Rear Left window";
CM_ SG_ 851 L_RLD_Wdw_LocalSwitch "Local switch status of Rear Left window";
CM_ SG_ 851 L_RLD_Wdw_PositionSts "Position status of Rear Left window";
CM_ SG_ 851 L_RLD_Val_Wdw_Opened "Window Opened Value";
CM_ SG_ 851 L_RLD_Motor_Ripple_Error "Motor ripple Error";
CM_ SG_ 851 L_RLD_Motor_Relay_Error "Motor relay Error";
CM_ SG_ 851 L_RLD_OverHeat_Protect "OverHeat Protect";
CM_ SG_ 851 L_RLD_Wdw_Init "ECU Initialization";
CM_ SG_ 851 L_RLD_Wdw_OD_Sts "Obstacle detection status";
CM_ SG_ 851 L_RLD_Wdw_Obs_InhibitSts "Obstacle inhibit status";
CM_ SG_ 851 RAPWL_01_LIN_Response_Error "LIN Communication ERROR";
CM_ SG_ 851 L_RRD_Wdw_Running_Sts "Running status of Rear Right window";
CM_ SG_ 851 L_RRD_Wdw_LocalSwitch "Local switch status of Rear Right window";
CM_ SG_ 851 L_RRD_Wdw_PositionSts "Position status of Rear Right window";
CM_ SG_ 851 L_RRD_Val_Wdw_Opened "Window Opened Value";
CM_ SG_ 851 L_RRD_Motor_Ripple_Error "Motor ripple Error";
CM_ SG_ 851 L_RRD_Motor_Relay_Error "Motor relay Error";
CM_ SG_ 851 L_RRD_OverHeat_Protect "OverHeat Protect";
CM_ SG_ 851 L_RRD_Wdw_Init "ECU Initialization";
CM_ SG_ 851 L_RRD_Wdw_OD_Sts "Obstacle detection status";
CM_ SG_ 851 L_RRD_Wdw_Obs_InhibitSts "Obstacle inhibit status";
CM_ SG_ 851 PTG_Inner_SW_2 "Power Tail Gate Inner SW#2 State";
CM_ SG_ 854 L_Drv_Wdw_Running_Sts "Running status of driver window";
CM_ SG_ 854 L_Drv_Wdw_LocalSwitch "Local switch status of driver window";
CM_ SG_ 854 L_Drv_Wdw_PositionSts "Position status of driver window";
CM_ SG_ 854 L_Drv_Val_Wdw_Opened "Window Opened Value";
CM_ SG_ 854 L_Drv_Motor_Ripple_Error "Motor ripple Error";
CM_ SG_ 854 L_Drv_Motor_Relay_Error "Motor relay Error";
CM_ SG_ 854 L_Drv_OverHeat_Protect "OverHeat Protect";
CM_ SG_ 854 L_Drv_Wdw_Init "ECU Initialization";
CM_ SG_ 854 L_Drv_Wdw_OD_Sts "Obstacle detection status";
CM_ SG_ 854 L_Drv_Wdw_Obs_InhibitSts "Obstacle inhibit status";
CM_ SG_ 854 FAPWL_01_LIN_Response_Error "LIN Communication ERROR";
CM_ SG_ 854 L_Power_Status "Power_Status";
CM_ SG_ 854 L_Pas_Wdw_Running_Sts "Running status of passager window";
CM_ SG_ 854 L_Pas_Wdw_LocalSwitch "Local switch status of passager window";
CM_ SG_ 854 L_Pas_Wdw_PositionSts "Position status of passager window";
CM_ SG_ 854 L_Pas_Val_Wdw_Opened "Window Opened Value";
CM_ SG_ 854 L_Pas_Motor_Ripple_Error "Motor ripple Error";
CM_ SG_ 854 L_Pas_Motor_Relay_Error "Motor relay Error";
CM_ SG_ 854 L_Pas_OverHeat_Protect "OverHeat Protect";
CM_ SG_ 854 L_Pas_Wdw_Init "ECU Initialization";
CM_ SG_ 854 L_Pas_Wdw_OD_Sts "Obstacle detection status";
CM_ SG_ 854 L_Pas_Wdw_Obs_InhibitSts "Obstacle inhibit status";
CM_ SG_ 854 L_Drv_Wdw_Pas_Switch "Passager switch status of driver window";
CM_ SG_ 854 L_Drv_Wdw_RLD_Switch "Passager switch status of Rear Left window";
CM_ SG_ 854 L_Drv_Wdw_RRD_Switch "Passager switch status of Rear Right window";
CM_ SG_ 854 L_APM_IntellectClose "Rainfall intelligent window raising";
BA_DEF_ BO_ "GenMsgSendType" ENUM "Cycle","NoMsgSendType","IfActive","Event","CA","CE";
BA_DEF_ BO_ "GenMsgNrOfRepetition" INT 0 0;
BA_DEF_ BO_ "GenMsgILSupport" ENUM "No","Yes";
BA_DEF_ BO_ "GenMsgDelayTime" INT 0 0;
BA_DEF_ BO_ "GenMsgCycleTimeFast" INT 0 0;
BA_DEF_ BO_ "GenMsgCycleTime" INT 0 0;
BA_DEF_ BO_ "DiagResponse" ENUM "No","Yes";
BA_DEF_ BO_ "DiagRequest" ENUM "No","Yes";
BA_DEF_ BO_ "NmMessage" ENUM "No","Yes";
BA_DEF_ BO_ "VFrameFormat" ENUM "StandardCAN","ExtendedCAN","reserved","reserved","reserved","reserved","reserved","reserved","reserved","reserved","reserved","reserved","reserved","reserved","StandardCAN_FD","ExtendedCAN_FD";
BA_DEF_ BO_ "GenMsgRequestable" INT 0 1;
BA_DEF_ BO_ "DataID_Hex" HEX 0 65535;
BA_DEF_ BO_ "DoIPLogicalAddress" STRING ;
BA_DEF_ BO_ "DataID" STRING ;
BA_DEF_ BO_ "CANFD_BRS" ENUM "0","1";
BA_DEF_ SG_ "GenSigInvalidValue" HEX 0 0;
BA_DEF_ SG_ "GenSigStartValue" HEX 0 0;
BA_DEF_ SG_ "GenSigInactiveValue" HEX 0 0;
BA_DEF_ SG_ "GenSigRoutingTimeoutValue_String" STRING ;
BA_DEF_ SG_ "GenSigRoutingTimeoutValue" HEX 0 0;
BA_DEF_ SG_ "GenSigSendType" ENUM "Cycle","OnWrite","OnWriteWithRepetition","OnChange","OnChangeWithRepetition","IfActive","IfActiveWithRepetition","NoSigSendType","vector_leerstring";
BA_DEF_ SG_ "SigType" ENUM "Default","Range","RangeSigned","ASCII","Discrete","Control","ReferencePGN","DTC","StringDelimiter","StringLength","StringLengthControl","MessageCounter","MessageChecksum";
BA_DEF_ SG_ "GenSigILSupport" ENUM "No","Yes";
BA_DEF_DEF_ "GenMsgSendType" "Cycle";
BA_DEF_DEF_ "GenMsgNrOfRepetition" 0;
BA_DEF_DEF_ "GenMsgILSupport" "Yes";
BA_DEF_DEF_ "GenMsgDelayTime" 0;
BA_DEF_DEF_ "GenMsgCycleTimeFast" 0;
BA_DEF_DEF_ "GenMsgCycleTime" 100;
BA_DEF_DEF_ "DiagResponse" "No";
BA_DEF_DEF_ "DiagRequest" "No";
BA_DEF_DEF_ "NmMessage" "No";
BA_DEF_DEF_ "VFrameFormat" "StandardCAN";
BA_DEF_DEF_ "GenMsgRequestable" 1;
BA_DEF_DEF_ "DataID_Hex" 0;
BA_DEF_DEF_ "DoIPLogicalAddress" "";
BA_DEF_DEF_ "DataID" "";
BA_DEF_DEF_ "CANFD_BRS" "1";
BA_DEF_DEF_ "GenSigInvalidValue" 0;
BA_DEF_DEF_ "GenSigStartValue" 0;
BA_DEF_DEF_ "GenSigInactiveValue" 0;
BA_DEF_DEF_ "GenSigRoutingTimeoutValue_String" "";
BA_DEF_DEF_ "GenSigRoutingTimeoutValue" 0;
BA_DEF_DEF_ "GenSigSendType" "Cycle";
BA_DEF_DEF_ "SigType" "Default";
BA_DEF_DEF_ "GenSigILSupport" "Yes";
BA_ "GenMsgNrOfRepetition" BO_ 535 1;
BA_ "GenMsgCycleTime" BO_ 535 200;
BA_ "GenMsgCycleTimeFast" BO_ 535 10;
BA_ "GenMsgSendType" BO_ 535 5;
BA_ "VFrameFormat" BO_ 535 14;
BA_ "GenMsgNrOfRepetition" BO_ 547 1;
BA_ "GenMsgCycleTimeFast" BO_ 547 50;
BA_ "VFrameFormat" BO_ 547 14;
BA_ "GenMsgNrOfRepetition" BO_ 550 1;
BA_ "GenMsgCycleTime" BO_ 550 200;
BA_ "GenMsgCycleTimeFast" BO_ 550 50;
BA_ "GenMsgSendType" BO_ 550 5;
BA_ "VFrameFormat" BO_ 550 14;
BA_ "GenMsgNrOfRepetition" BO_ 552 1;
BA_ "GenMsgCycleTime" BO_ 552 200;
BA_ "GenMsgCycleTimeFast" BO_ 552 50;
BA_ "GenMsgSendType" BO_ 552 5;
BA_ "VFrameFormat" BO_ 552 14;
BA_ "GenMsgCycleTime" BO_ 553 10;
BA_ "VFrameFormat" BO_ 553 14;
BA_ "GenMsgCycleTime" BO_ 566 20;
BA_ "VFrameFormat" BO_ 566 14;
BA_ "GenMsgCycleTime" BO_ 568 10;
BA_ "VFrameFormat" BO_ 568 14;
BA_ "GenMsgNrOfRepetition" BO_ 570 1;
BA_ "GenMsgCycleTimeFast" BO_ 570 10;
BA_ "VFrameFormat" BO_ 570 14;
BA_ "GenMsgNrOfRepetition" BO_ 572 1;
BA_ "GenMsgCycleTimeFast" BO_ 572 10;
BA_ "VFrameFormat" BO_ 572 14;
BA_ "GenMsgCycleTime" BO_ 581 500;
BA_ "VFrameFormat" BO_ 581 14;
BA_ "GenMsgNrOfRepetition" BO_ 659 1;
BA_ "GenMsgCycleTimeFast" BO_ 659 10;
BA_ "GenMsgSendType" BO_ 659 5;
BA_ "VFrameFormat" BO_ 659 14;
BA_ "GenMsgCycleTime" BO_ 809 1000;
BA_ "VFrameFormat" BO_ 809 14;
BA_ "VFrameFormat" BO_ 820 14;
BA_ "GenMsgNrOfRepetition" BO_ 826 1;
BA_ "GenMsgCycleTime" BO_ 826 200;
BA_ "GenMsgCycleTimeFast" BO_ 826 10;
BA_ "GenMsgSendType" BO_ 826 5;
BA_ "VFrameFormat" BO_ 826 14;
BA_ "GenMsgNrOfRepetition" BO_ 851 1;
BA_ "GenMsgSendType" BO_ 851 5;
BA_ "VFrameFormat" BO_ 851 14;
BA_ "VFrameFormat" BO_ 854 14;
BA_ "GenSigSendType" SG_ 535 AmbLightBrightness1 3;
BA_ "GenSigSendType" SG_ 535 AmbLightBrightness2 3;
BA_ "GenSigSendType" SG_ 535 AmbLightBrightness3 3;
BA_ "GenSigSendType" SG_ 535 AmbLightColor1 3;
BA_ "GenSigSendType" SG_ 535 AmbLightColor2 3;
BA_ "GenSigSendType" SG_ 535 AmbLightColor3 3;
BA_ "GenSigSendType" SG_ 535 User1AmbLightColor 3;
BA_ "GenSigSendType" SG_ 535 User2AmbLightColor 3;
BA_ "GenSigSendType" SG_ 535 User3AmbLightColor 3;
BA_ "GenSigSendType" SG_ 535 User4AmbLightColor 3;
BA_ "GenSigSendType" SG_ 535 User5AmbLightColor 3;
BA_ "GenSigSendType" SG_ 535 User6AmbLightColor 3;
BA_ "GenSigSendType" SG_ 535 User1IPAmbLightBrightness 3;
BA_ "GenSigSendType" SG_ 535 User2IPAmbLightBrightness 3;
BA_ "GenSigSendType" SG_ 535 User3IPAmbLightBrightness 3;
BA_ "GenSigSendType" SG_ 535 User4IPAmbLightBrightness 3;
BA_ "GenSigSendType" SG_ 535 User5IPAmbLightBrightness 3;
BA_ "GenSigSendType" SG_ 535 User6IPAmbLightBrightness 3;
BA_ "GenSigSendType" SG_ 535 User1DrAmbLightBrightness 3;
BA_ "GenSigSendType" SG_ 535 User2DrAmbLightBrightness 3;
BA_ "GenSigSendType" SG_ 535 User3DrAmbLightBrightness 3;
BA_ "GenSigSendType" SG_ 535 LampPwr 3;
BA_ "GenSigSendType" SG_ 535 User4DrAmbLightBrightness 3;
BA_ "GenSigSendType" SG_ 535 AmbLightBreath1 3;
BA_ "GenSigSendType" SG_ 535 User5DrAmbLightBrightness 3;
BA_ "GenSigSendType" SG_ 535 AmbLightBreath2 3;
BA_ "GenSigSendType" SG_ 535 User6DrAmbLightBrightness 3;
BA_ "GenSigSendType" SG_ 535 AmbLightBreath3 3;
BA_ "GenSigStartValue" SG_ 547 FrntPTCPCBT 255;
BA_ "GenSigStartValue" SG_ 547 FrntPTCRiIGBTT 255;
BA_ "GenSigStartValue" SG_ 547 FrntPTCLeIGBTT 255;
BA_ "GenSigStartValue" SG_ 547 FrntPTCRiActHeatPwr 255;
BA_ "GenSigStartValue" SG_ 547 FrntPTCLeActHeatPwr 255;
BA_ "GenSigStartValue" SG_ 547 FrntPTCRiCoreT 255;
BA_ "GenSigStartValue" SG_ 547 FrntPTCLeCoreT 255;
BA_ "GenSigSendType" SG_ 550 DrLockSta 3;
BA_ "GenSigSendType" SG_ 550 PsLockSta 3;
BA_ "GenSigSendType" SG_ 550 RLLockSta 3;
BA_ "GenSigSendType" SG_ 550 RRLockSta 3;
BA_ "GenSigSendType" SG_ 550 AllLockSta 3;
BA_ "GenSigSendType" SG_ 550 MIRROR_FOLD_SW 3;
BA_ "GenSigSendType" SG_ 550 RWiperAS 3;
BA_ "GenSigSendType" SG_ 550 RWiperProtection 3;
BA_ "GenSigSendType" SG_ 550 Wip_Speed 3;
BA_ "GenSigRoutingTimeoutValue" SG_ 550 CSW_RWipIntSw_Sta 3;
BA_ "GenSigSendType" SG_ 550 CSW_RWipIntSw_Sta 3;
BA_ "GenSigSendType" SG_ 550 CSW_DimSw 3;
BA_ "GenSigSendType" SG_ 550 BrakeLampFail 3;
BA_ "GenSigSendType" SG_ 550 CSW_PassSW_Sta 3;
BA_ "GenSigSendType" SG_ 550 RLS_Exist 3;
BA_ "GenSigSendType" SG_ 550 RLTurnLampC 3;
BA_ "GenSigSendType" SG_ 550 RRTurnLampC 3;
BA_ "GenSigRoutingTimeoutValue" SG_ 550 CSW_FWasSw_Sta 3;
BA_ "GenSigSendType" SG_ 550 CSW_FWasSw_Sta 3;
BA_ "GenSigRoutingTimeoutValue" SG_ 550 CSW_RWasSW_Sta 3;
BA_ "GenSigSendType" SG_ 550 CSW_RWasSW_Sta 3;
BA_ "GenSigRoutingTimeoutValue" SG_ 550 CSW_TurnSw_Sta 3;
BA_ "GenSigSendType" SG_ 550 CSW_TurnSw_Sta 3;
BA_ "GenSigSendType" SG_ 550 HornSW 3;
BA_ "GenSigRoutingTimeoutValue" SG_ 550 CSW_FWipSw_Sta 7;
BA_ "GenSigSendType" SG_ 550 CSW_FWipSw_Sta 3;
BA_ "GenSigSendType" SG_ 550 RLS_RainSnrWiperCmd 3;
BA_ "GenSigSendType" SG_ 550 RLS_Lamp_Sta 3;
BA_ "GenSigSendType" SG_ 550 WiperSWPos 3;
BA_ "GenSigSendType" SG_ 550 CSW_resp_error 3;
BA_ "GenSigSendType" SG_ 550 AutoLightSW 3;
BA_ "GenSigSendType" SG_ 550 WiperZeroPosSW 3;
BA_ "GenSigSendType" SG_ 550 RLS_RainSnrErr 3;
BA_ "GenSigSendType" SG_ 550 RLS_LightSnrErr 3;
BA_ "GenSigSendType" SG_ 550 RLS_LIN_Resp_Err 3;
BA_ "GenSigInvalidValue" SG_ 552 EWP1_RPM_Target_EWP_Rq 255;
BA_ "GenSigInvalidValue" SG_ 552 EWP3_RPM_Target_EWP_Rq 255;
BA_ "GenSigInvalidValue" SG_ 552 EWP2_RPM_Target_EWP_Rq 255;
BA_ "GenSigSendType" SG_ 552 FWiperAS 3;
BA_ "GenSigSendType" SG_ 552 FWiperProtection 3;
BA_ "GenSigSendType" SG_ 552 FLTurnLampC 3;
BA_ "GenSigSendType" SG_ 552 FRTurnLampC 3;
BA_ "GenSigStartValue" SG_ 552 AGS_Actual_Position 127;
BA_ "GenSigStartValue" SG_ 553 EPS_Pwr_Consumpt_V 1;
BA_ "GenSigStartValue" SG_ 553 EPS_VOL_V 1;
BA_ "GenSigStartValue" SG_ 553 EPS_Temp_V 1;
BA_ "GenSigStartValue" SG_ 553 EPS_Pwr_Limit_V 1;
BA_ "GenSigStartValue" SG_ 553 Steering_Torque_V 1;
BA_ "GenSigStartValue" SG_ 553 EPS_Temp 100;
BA_ "GenSigInvalidValue" SG_ 566 APS_Angle_Target 65535;
BA_ "GenSigSendType" SG_ 659 Set_Spd 3;
BA_ "GenSigInvalidValue" SG_ 659 RegenMode 7;
BA_ "GenSigSendType" SG_ 659 RegenMode 3;
BA_ "GenSigSendType" SG_ 659 Zone_Spd_Ctrl_Sta 3;
BA_ "GenSigInvalidValue" SG_ 659 Zone_Spd_Ctrl_Mode 5;
BA_ "GenSigSendType" SG_ 659 Zone_Spd_Ctrl_Mode 3;
BA_ "GenSigInvalidValue" SG_ 809 HVBattSOCDis 255;
BA_ "GenSigInvalidValue" SG_ 809 HVBattSOC 255;
BA_ "GenSigInvalidValue" SG_ 809 HVBChrgPwr 1023;
BA_ "GenSigInvalidValue" SG_ 809 HVBDrvPwr 1023;
BA_ "GenSigInvalidValue" SG_ 809 HVBFullChrgPwr 1023;
BA_ "GenSigInvalidValue" SG_ 809 HVBSOH 255;
BA_ "GenSigInvalidValue" SG_ 809 Battsystfail_Num 255;
BA_ "GenSigInvalidValue" SG_ 809 RechrgCyc 262143;
BA_ "GenSigInvalidValue" SG_ 809 ACChrgCurrDis 32767;
BA_ "GenSigStartValue" SG_ 809 ACChrgCurrDis 10000;
BA_ "GenSigSendType" SG_ 826 SWC_LKA_Sta 3;
BA_ "GenSigSendType" SG_ 826 SWC_Undefined_Sta 3;
BA_ "GenSigSendType" SG_ 826 SWC_VR_Sta 3;
BA_ "GenSigSendType" SG_ 826 SWC_Up_Sta 3;
BA_ "GenSigSendType" SG_ 826 SWC_Trip_Sta 3;
BA_ "GenSigSendType" SG_ 826 SWC_Set_down_Sta 3;
BA_ "GenSigSendType" SG_ 826 SWC_Right_Sta 3;
BA_ "GenSigSendType" SG_ 826 SWC_RegenDown 1;
BA_ "GenSigSendType" SG_ 826 SWC_Res_Up_Sta 3;
BA_ "GenSigSendType" SG_ 826 SWC_mode_Sta 3;
BA_ "GenSigSendType" SG_ 826 SWC_Left_Sta 3;
BA_ "GenSigSendType" SG_ 826 SWC_RegenUp 3;
BA_ "GenSigSendType" SG_ 826 SWC_Down_Sta 3;
BA_ "GenSigSendType" SG_ 826 SWC_Distance_Sta 3;
BA_ "GenSigSendType" SG_ 826 SWC_ACC_Sta 3;
BA_ "GenSigSendType" SG_ 826 SWC_CANCEL_Sta 3;
BA_ "GenSigRoutingTimeoutValue" SG_ 851 L_RLD_Wdw_PositionSts 3;
BA_ "GenSigRoutingTimeoutValue" SG_ 851 L_RLD_Val_Wdw_Opened 127;
BA_ "GenSigRoutingTimeoutValue" SG_ 851 L_RRD_Wdw_PositionSts 3;
BA_ "GenSigRoutingTimeoutValue" SG_ 851 L_RRD_Val_Wdw_Opened 127;
BA_ "GenSigSendType" SG_ 851 PTG_Inner_SW_2 3;
BA_ "GenSigRoutingTimeoutValue" SG_ 854 L_Drv_Wdw_PositionSts 3;
BA_ "GenSigRoutingTimeoutValue" SG_ 854 L_Drv_Val_Wdw_Opened 127;
BA_ "GenSigRoutingTimeoutValue" SG_ 854 L_Pas_Wdw_PositionSts 3;
BA_ "GenSigRoutingTimeoutValue" SG_ 854 L_Pas_Val_Wdw_Opened 127;
VAL_ 535 AmbLightBrightness1 101 "~0x7F Invalid" 100 "100%" 99 "99%" 98 "98%" 97 "97%" 96 "96%" 95 "95%" 94 "94%" 93 "93%" 92 "92%" 91 "91%" 90 "90%" 89 "89%" 88 "88%" 87 "87%" 86 "86%" 85 "85%" 84 "84%" 83 "83%" 82 "82%" 81 "81%" 80 "80%" 79 "79%" 78 "78%" 77 "77%" 76 "76%" 75 "75%" 74 "74%" 73 "73%" 72 "72%" 71 "71%" 70 "70%" 69 "69%" 68 "68%" 67 "67%" 66 "66%" 65 "65%" 64 "64%" 63 "63%" 62 "62%" 61 "61%" 60 "60%" 59 "59%" 58 "58%" 57 "57%" 56 "56%" 55 "55%" 54 "54%" 53 "53%" 52 "52%" 51 "51%" 50 "50%" 49 "49%" 48 "48%" 47 "47%" 46 "46%" 45 "45%" 44 "44%" 43 "43%" 42 "42%" 41 "41%" 40 "40%" 39 "39%" 38 "38%" 37 "37%" 36 "36%" 35 "35%" 34 "34%" 33 "33%" 32 "32%" 31 "31%" 30 "30%" 29 "29%" 28 "28%" 27 "27%" 26 "26%" 25 "25%" 24 "24%" 23 "23%" 22 "22%" 21 "21%" 20 "20%" 19 "19%" 18 "18%" 17 "17%" 16 "16%" 15 "15%" 14 "14%" 13 "13%" 12 "12%" 11 "11%" 10 "10%" 9 "9%" 8 "8%" 7 "7%" 6 "6%" 5 "5%" 4 "4%" 3 "3%" 2 "2%" 1 "1%" 0 "0%";
VAL_ 535 AmbLightBrightness2 101 "~0x7F Valid" 100 "100%" 99 "99%" 98 "98%" 97 "97%" 96 "96%" 95 "95%" 94 "94%" 93 "93%" 92 "92%" 91 "91%" 90 "90%" 89 "89%" 88 "88%" 87 "87%" 86 "86%" 85 "85%" 84 "84%" 83 "83%" 82 "82%" 81 "81%" 80 "80%" 79 "79%" 78 "78%" 77 "77%" 76 "76%" 75 "75%" 74 "74%" 73 "73%" 72 "72%" 71 "71%" 70 "70%" 69 "69%" 68 "68%" 67 "67%" 66 "66%" 65 "65%" 64 "64%" 63 "63%" 62 "62%" 61 "61%" 60 "60%" 59 "59%" 58 "58%" 57 "57%" 56 "56%" 55 "55%" 54 "54%" 53 "53%" 52 "52%" 51 "51%" 50 "50%" 49 "49%" 48 "48%" 47 "47%" 46 "46%" 45 "45%" 44 "44%" 43 "43%" 42 "42%" 41 "41%" 40 "40%" 39 "39%" 38 "38%" 37 "37%" 36 "36%" 35 "35%" 34 "34%" 33 "33%" 32 "32%" 31 "31%" 30 "30%" 29 "29%" 28 "28%" 27 "27%" 26 "26%" 25 "25%" 24 "24%" 23 "23%" 22 "22%" 21 "21%" 20 "20%" 19 "19%" 18 "18%" 17 "17%" 16 "16%" 15 "15%" 14 "14%" 13 "13%" 12 "12%" 11 "11%" 10 "10%" 9 "9%" 8 "8%" 7 "7%" 6 "6%" 5 "5%" 4 "4%" 3 "3%" 2 "2%" 1 "1%" 0 "0%";
VAL_ 535 AmbLightBrightness3 101 "~0x7F Valid" 100 "100%" 99 "99%" 98 "98%" 97 "97%" 96 "96%" 95 "95%" 94 "94%" 93 "93%" 92 "92%" 91 "91%" 90 "90%" 89 "89%" 88 "88%" 87 "87%" 86 "86%" 85 "85%" 84 "84%" 83 "83%" 82 "82%" 81 "81%" 80 "80%" 79 "79%" 78 "78%" 77 "77%" 76 "76%" 75 "75%" 74 "74%" 73 "73%" 72 "72%" 71 "71%" 70 "70%" 69 "69%" 68 "68%" 67 "67%" 66 "66%" 65 "65%" 64 "64%" 63 "63%" 62 "62%" 61 "61%" 60 "60%" 59 "59%" 58 "58%" 57 "57%" 56 "56%" 55 "55%" 54 "54%" 53 "53%" 52 "52%" 51 "51%" 50 "50%" 49 "49%" 48 "48%" 47 "47%" 46 "46%" 45 "45%" 44 "44%" 43 "43%" 42 "42%" 41 "41%" 40 "40%" 39 "39%" 38 "38%" 37 "37%" 36 "36%" 35 "35%" 34 "34%" 33 "33%" 32 "32%" 31 "31%" 30 "30%" 29 "29%" 28 "28%" 27 "27%" 26 "26%" 25 "25%" 24 "24%" 23 "23%" 22 "22%" 21 "21%" 20 "20%" 19 "19%" 18 "18%" 17 "17%" 16 "16%" 15 "15%" 14 "14%" 13 "13%" 12 "12%" 11 "11%" 10 "10%" 9 "9%" 8 "8%" 7 "7%" 6 "6%" 5 "5%" 4 "4%" 3 "3%" 2 "2%" 1 "1%" 0 "0%";
VAL_ 535 AmbLightColor1 63 "Red(255,0,0)" 62 "IndianRed(205,92,92)" 61 "LightCoral(240,128,128)" 60 "Tomato(255,99,71)" 59 "OrangeRed(255,69,0)" 58 "Coral(255,127,80)" 57 "LightSalmon(255,160,122)" 56 "DarkOrange(255,140,0)" 55 "Bisque(255,228,196)" 54 "NavajoWhite(255,222,173)" 53 "BlanchedAlmond(255,235,205)" 52 "Gold(255,215,0)" 51 "LemonChiffon(255,250,205)" 50 "Yellow(255,255,0)" 49 "LightYellow(255,255,224)" 48 "Ivory(255,255,240)" 47 "LightGoldenrodYellow(250,250,210)" 46 "Beige(245,245,220)" 45 "GreenYellow(173,255,47)" 44 "Chartreuse(127,255,0)" 43 "Lime(0,255,0)" 42 "LimeGreen(50,205,50)" 41 "PaleGreen(152,251,152)" 40 "LightGreen(144,238,144)" 39 "SeaGreen(46,139,87)" 38 "SpringGreen(60,179,113)" 37 "MediumSpringGreen(0,255,127)" 36 "MediumAquamarine(0,250,154)" 35 "Auqamarin(127,255,170)" 34 "MediumTurquoise(72,209,204)" 33 "DarkCyan(0,139,139)" 32 "DarkTurquoise(0,206,209)" 31 "Cyan(0,255,255)" 30 "PaleTurquoise(175,238,238)" 29 "DeepSkyBlue(0,191,255)" 28 "SkyBlue(135,206,235)" 27 "LightSkyBlue(135,206,250)" 26 "DoderBlue(30,144,255)" 25 "CornflowerBlue(100,149,237)" 24 "RoyalBlue(65,105,225)" 23 "Navy(0,0,128)" 22 "DarkBlue(0,0,139)" 21 "MidnightBlue(25,25,112)" 20 "MediumBlue(0,0,205)" 19 "Blue(0,0,255)" 18 "DarkSlateBlue(72,61,139)" 17 "SlateBlue(106,90,205)" 16 "MediumSlateBlue(123,104,238)" 15 "MediumPurple(147,112,219)" 14 "BlueViolet(138,43,226)" 13 "Indigo(75,0,130)" 12 "DarkOrchid(153,50,204)" 11 "DarkVoilet(148,0,211)" 10 "MediumOrchid(186,85,211)" 9 "DarkMagenta(139,0,139)" 8 "Magenta(255,0,255)" 7 "Violet(238,130,238)" 6 "Orchid(218,112,214)" 5 "MediumVioletRed(199,21,133)" 4 "DeepPink(255,20,147)" 3 "HotPink(255,105,180)" 2 "PaleVioletRed(219,112,147)" 1 "Crimson(220,20,60)" 0 "LightPink(255,182,193)";
VAL_ 535 AmbLightColor2 63 "Red(255,0,0)" 62 "IndianRed(205,92,92)" 61 "LightCoral(240,128,128)" 60 "Tomato(255,99,71)" 59 "OrangeRed(255,69,0)" 58 "Coral(255,127,80)" 57 "LightSalmon(255,160,122)" 56 "DarkOrange(255,140,0)" 55 "Bisque(255,228,196)" 54 "NavajoWhite(255,222,173)" 53 "BlanchedAlmond(255,235,205)" 52 "Gold(255,215,0)" 51 "LemonChiffon(255,250,205)" 50 "Yellow(255,255,0)" 49 "LightYellow(255,255,224)" 48 "Ivory(255,255,240)" 47 "LightGoldenrodYellow(250,250,210)" 46 "Beige(245,245,220)" 45 "GreenYellow(173,255,47)" 44 "Chartreuse(127,255,0)" 43 "Lime(0,255,0)" 42 "LimeGreen(50,205,50)" 41 "PaleGreen(152,251,152)" 40 "LightGreen(144,238,144)" 39 "SeaGreen(46,139,87)" 38 "SpringGreen(60,179,113)" 37 "MediumSpringGreen(0,255,127)" 36 "MediumAquamarine(0,250,154)" 35 "Auqamarin(127,255,170)" 34 "MediumTurquoise(72,209,204)" 33 "DarkCyan(0,139,139)" 32 "DarkTurquoise(0,206,209)" 31 "Cyan(0,255,255)" 30 "PaleTurquoise(175,238,238)" 29 "DeepSkyBlue(0,191,255)" 28 "SkyBlue(135,206,235)" 27 "LightSkyBlue(135,206,250)" 26 "DoderBlue(30,144,255)" 25 "CornflowerBlue(100,149,237)" 24 "RoyalBlue(65,105,225)" 23 "Navy(0,0,128)" 22 "DarkBlue(0,0,139)" 21 "MidnightBlue(25,25,112)" 20 "MediumBlue(0,0,205)" 19 "Blue(0,0,255)" 18 "DarkSlateBlue(72,61,139)" 17 "SlateBlue(106,90,205)" 16 "MediumSlateBlue(123,104,238)" 15 "MediumPurple(147,112,219)" 14 "BlueViolet(138,43,226)" 13 "Indigo(75,0,130)" 12 "DarkOrchid(153,50,204)" 11 "DarkVoilet(148,0,211)" 10 "MediumOrchid(186,85,211)" 9 "DarkMagenta(139,0,139)" 8 "Magenta(255,0,255)" 7 "Violet(238,130,238)" 6 "Orchid(218,112,214)" 5 "MediumVioletRed(199,21,133)" 4 "DeepPink(255,20,147)" 3 "HotPink(255,105,180)" 2 "PaleVioletRed(219,112,147)" 1 "Crimson(220,20,60)" 0 "LightPink(255,182,193)";
VAL_ 535 AmbLightColor3 63 "Red(255,0,0)" 62 "IndianRed(205,92,92)" 61 "LightCoral(240,128,128)" 60 "Tomato(255,99,71)" 59 "OrangeRed(255,69,0)" 58 "Coral(255,127,80)" 57 "LightSalmon(255,160,122)" 56 "DarkOrange(255,140,0)" 55 "Bisque(255,228,196)" 54 "NavajoWhite(255,222,173)" 53 "BlanchedAlmond(255,235,205)" 52 "Gold(255,215,0)" 51 "LemonChiffon(255,250,205)" 50 "Yellow(255,255,0)" 49 "LightYellow(255,255,224)" 48 "Ivory(255,255,240)" 47 "LightGoldenrodYellow(250,250,210)" 46 "Beige(245,245,220)" 45 "GreenYellow(173,255,47)" 44 "Chartreuse(127,255,0)" 43 "Lime(0,255,0)" 42 "LimeGreen(50,205,50)" 41 "PaleGreen(152,251,152)" 40 "LightGreen(144,238,144)" 39 "SeaGreen(46,139,87)" 38 "SpringGreen(60,179,113)" 37 "MediumSpringGreen(0,255,127)" 36 "MediumAquamarine(0,250,154)" 35 "Auqamarin(127,255,170)" 34 "MediumTurquoise(72,209,204)" 33 "DarkCyan(0,139,139)" 32 "DarkTurquoise(0,206,209)" 31 "Cyan(0,255,255)" 30 "PaleTurquoise(175,238,238)" 29 "DeepSkyBlue(0,191,255)" 28 "SkyBlue(135,206,235)" 27 "LightSkyBlue(135,206,250)" 26 "DoderBlue(30,144,255)" 25 "CornflowerBlue(100,149,237)" 24 "RoyalBlue(65,105,225)" 23 "Navy(0,0,128)" 22 "DarkBlue(0,0,139)" 21 "MidnightBlue(25,25,112)" 20 "MediumBlue(0,0,205)" 19 "Blue(0,0,255)" 18 "DarkSlateBlue(72,61,139)" 17 "SlateBlue(106,90,205)" 16 "MediumSlateBlue(123,104,238)" 15 "MediumPurple(147,112,219)" 14 "BlueViolet(138,43,226)" 13 "Indigo(75,0,130)" 12 "DarkOrchid(153,50,204)" 11 "DarkVoilet(148,0,211)" 10 "MediumOrchid(186,85,211)" 9 "DarkMagenta(139,0,139)" 8 "Magenta(255,0,255)" 7 "Violet(238,130,238)" 6 "Orchid(218,112,214)" 5 "MediumVioletRed(199,21,133)" 4 "DeepPink(255,20,147)" 3 "HotPink(255,105,180)" 2 "PaleVioletRed(219,112,147)" 1 "Crimson(220,20,60)" 0 "LightPink(255,182,193)";
VAL_ 535 User1AmbLightColor 63 "Red(255,0,0)" 62 "IndianRed(205,92,92)" 61 "LightCoral(240,128,128)" 60 "Tomato(255,99,71)" 59 "OrangeRed(255,69,0)" 58 "Coral(255,127,80)" 57 "LightSalmon(255,160,122)" 56 "DarkOrange(255,140,0)" 55 "Bisque(255,228,196)" 54 "NavajoWhite(255,222,173)" 53 "BlanchedAlmond(255,235,205)" 52 "Gold(255,215,0)" 51 "LemonChiffon(255,250,205)" 50 "Yellow(255,255,0)" 49 "LightYellow(255,255,224)" 48 "Ivory(255,255,240)" 47 "LightGoldenrodYellow(250,250,210)" 46 "Beige(245,245,220)" 45 "GreenYellow(173,255,47)" 44 "Chartreuse(127,255,0)" 43 "Lime(0,255,0)" 42 "LimeGreen(50,205,50)" 41 "PaleGreen(152,251,152)" 40 "LightGreen(144,238,144)" 39 "SeaGreen(46,139,87)" 38 "SpringGreen(60,179,113)" 37 "MediumSpringGreen(0,255,127)" 36 "MediumAquamarine(0,250,154)" 35 "Auqamarin(127,255,170)" 34 "MediumTurquoise(72,209,204)" 33 "DarkCyan(0,139,139)" 32 "DarkTurquoise(0,206,209)" 31 "Cyan(0,255,255)" 30 "PaleTurquoise(175,238,238)" 29 "DeepSkyBlue(0,191,255)" 28 "SkyBlue(135,206,235)" 27 "LightSkyBlue(135,206,250)" 26 "DoderBlue(30,144,255)" 25 "CornflowerBlue(100,149,237)" 24 "RoyalBlue(65,105,225)" 23 "Navy(0,0,128)" 22 "DarkBlue(0,0,139)" 21 "MidnightBlue(25,25,112)" 20 "MediumBlue(0,0,205)" 19 "Blue(0,0,255)" 18 "DarkSlateBlue(72,61,139)" 17 "SlateBlue(106,90,205)" 16 "MediumSlateBlue(123,104,238)" 15 "MediumPurple(147,112,219)" 14 "BlueViolet(138,43,226)" 13 "Indigo(75,0,130)" 12 "DarkOrchid(153,50,204)" 11 "DarkVoilet(148,0,211)" 10 "MediumOrchid(186,85,211)" 9 "DarkMagenta(139,0,139)" 8 "Magenta(255,0,255)" 7 "Violet(238,130,238)" 6 "Orchid(218,112,214)" 5 "MediumVioletRed(199,21,133)" 4 "DeepPink(255,20,147)" 3 "HotPink(255,105,180)" 2 "PaleVioletRed(219,112,147)" 1 "Crimson(220,20,60)" 0 "LightPink(255,182,193)";
VAL_ 535 User2AmbLightColor 63 "Red(255,0,0)" 62 "IndianRed(205,92,92)" 61 "LightCoral(240,128,128)" 60 "Tomato(255,99,71)" 59 "OrangeRed(255,69,0)" 58 "Coral(255,127,80)" 57 "LightSalmon(255,160,122)" 56 "DarkOrange(255,140,0)" 55 "Bisque(255,228,196)" 54 "NavajoWhite(255,222,173)" 53 "BlanchedAlmond(255,235,205)" 52 "Gold(255,215,0)" 51 "LemonChiffon(255,250,205)" 50 "Yellow(255,255,0)" 49 "LightYellow(255,255,224)" 48 "Ivory(255,255,240)" 47 "LightGoldenrodYellow(250,250,210)" 46 "Beige(245,245,220)" 45 "GreenYellow(173,255,47)" 44 "Chartreuse(127,255,0)" 43 "Lime(0,255,0)" 42 "LimeGreen(50,205,50)" 41 "PaleGreen(152,251,152)" 40 "LightGreen(144,238,144)" 39 "SeaGreen(46,139,87)" 38 "SpringGreen(60,179,113)" 37 "MediumSpringGreen(0,255,127)" 36 "MediumAquamarine(0,250,154)" 35 "Auqamarin(127,255,170)" 34 "MediumTurquoise(72,209,204)" 33 "DarkCyan(0,139,139)" 32 "DarkTurquoise(0,206,209)" 31 "Cyan(0,255,255)" 30 "PaleTurquoise(175,238,238)" 29 "DeepSkyBlue(0,191,255)" 28 "SkyBlue(135,206,235)" 27 "LightSkyBlue(135,206,250)" 26 "DoderBlue(30,144,255)" 25 "CornflowerBlue(100,149,237)" 24 "RoyalBlue(65,105,225)" 23 "Navy(0,0,128)" 22 "DarkBlue(0,0,139)" 21 "MidnightBlue(25,25,112)" 20 "MediumBlue(0,0,205)" 19 "Blue(0,0,255)" 18 "DarkSlateBlue(72,61,139)" 17 "SlateBlue(106,90,205)" 16 "MediumSlateBlue(123,104,238)" 15 "MediumPurple(147,112,219)" 14 "BlueViolet(138,43,226)" 13 "Indigo(75,0,130)" 12 "DarkOrchid(153,50,204)" 11 "DarkVoilet(148,0,211)" 10 "MediumOrchid(186,85,211)" 9 "DarkMagenta(139,0,139)" 8 "Magenta(255,0,255)" 7 "Violet(238,130,238)" 6 "Orchid(218,112,214)" 5 "MediumVioletRed(199,21,133)" 4 "DeepPink(255,20,147)" 3 "HotPink(255,105,180)" 2 "PaleVioletRed(219,112,147)" 1 "Crimson(220,20,60)" 0 "LightPink(255,182,193)";
VAL_ 535 User3AmbLightColor 63 "Red(255,0,0)" 62 "IndianRed(205,92,92)" 61 "LightCoral(240,128,128)" 60 "Tomato(255,99,71)" 59 "OrangeRed(255,69,0)" 58 "Coral(255,127,80)" 57 "LightSalmon(255,160,122)" 56 "DarkOrange(255,140,0)" 55 "Bisque(255,228,196)" 54 "NavajoWhite(255,222,173)" 53 "BlanchedAlmond(255,235,205)" 52 "Gold(255,215,0)" 51 "LemonChiffon(255,250,205)" 50 "Yellow(255,255,0)" 49 "LightYellow(255,255,224)" 48 "Ivory(255,255,240)" 47 "LightGoldenrodYellow(250,250,210)" 46 "Beige(245,245,220)" 45 "GreenYellow(173,255,47)" 44 "Chartreuse(127,255,0)" 43 "Lime(0,255,0)" 42 "LimeGreen(50,205,50)" 41 "PaleGreen(152,251,152)" 40 "LightGreen(144,238,144)" 39 "SeaGreen(46,139,87)" 38 "SpringGreen(60,179,113)" 37 "MediumSpringGreen(0,255,127)" 36 "MediumAquamarine(0,250,154)" 35 "Auqamarin(127,255,170)" 34 "MediumTurquoise(72,209,204)" 33 "DarkCyan(0,139,139)" 32 "DarkTurquoise(0,206,209)" 31 "Cyan(0,255,255)" 30 "PaleTurquoise(175,238,238)" 29 "DeepSkyBlue(0,191,255)" 28 "SkyBlue(135,206,235)" 27 "LightSkyBlue(135,206,250)" 26 "DoderBlue(30,144,255)" 25 "CornflowerBlue(100,149,237)" 24 "RoyalBlue(65,105,225)" 23 "Navy(0,0,128)" 22 "DarkBlue(0,0,139)" 21 "MidnightBlue(25,25,112)" 20 "MediumBlue(0,0,205)" 19 "Blue(0,0,255)" 18 "DarkSlateBlue(72,61,139)" 17 "SlateBlue(106,90,205)" 16 "MediumSlateBlue(123,104,238)" 15 "MediumPurple(147,112,219)" 14 "BlueViolet(138,43,226)" 13 "Indigo(75,0,130)" 12 "DarkOrchid(153,50,204)" 11 "DarkVoilet(148,0,211)" 10 "MediumOrchid(186,85,211)" 9 "DarkMagenta(139,0,139)" 8 "Magenta(255,0,255)" 7 "Violet(238,130,238)" 6 "Orchid(218,112,214)" 5 "MediumVioletRed(199,21,133)" 4 "DeepPink(255,20,147)" 3 "HotPink(255,105,180)" 2 "PaleVioletRed(219,112,147)" 1 "Crimson(220,20,60)" 0 "LightPink(255,182,193)";
VAL_ 535 User4AmbLightColor 63 "Red(255,0,0)" 62 "IndianRed(205,92,92)" 61 "LightCoral(240,128,128)" 60 "Tomato(255,99,71)" 59 "OrangeRed(255,69,0)" 58 "Coral(255,127,80)" 57 "LightSalmon(255,160,122)" 56 "DarkOrange(255,140,0)" 55 "Bisque(255,228,196)" 54 "NavajoWhite(255,222,173)" 53 "BlanchedAlmond(255,235,205)" 52 "Gold(255,215,0)" 51 "LemonChiffon(255,250,205)" 50 "Yellow(255,255,0)" 49 "LightYellow(255,255,224)" 48 "Ivory(255,255,240)" 47 "LightGoldenrodYellow(250,250,210)" 46 "Beige(245,245,220)" 45 "GreenYellow(173,255,47)" 44 "Chartreuse(127,255,0)" 43 "Lime(0,255,0)" 42 "LimeGreen(50,205,50)" 41 "PaleGreen(152,251,152)" 40 "LightGreen(144,238,144)" 39 "SeaGreen(46,139,87)" 38 "SpringGreen(60,179,113)" 37 "MediumSpringGreen(0,255,127)" 36 "MediumAquamarine(0,250,154)" 35 "Auqamarin(127,255,170)" 34 "MediumTurquoise(72,209,204)" 33 "DarkCyan(0,139,139)" 32 "DarkTurquoise(0,206,209)" 31 "Cyan(0,255,255)" 30 "PaleTurquoise(175,238,238)" 29 "DeepSkyBlue(0,191,255)" 28 "SkyBlue(135,206,235)" 27 "LightSkyBlue(135,206,250)" 26 "DoderBlue(30,144,255)" 25 "CornflowerBlue(100,149,237)" 24 "RoyalBlue(65,105,225)" 23 "Navy(0,0,128)" 22 "DarkBlue(0,0,139)" 21 "MidnightBlue(25,25,112)" 20 "MediumBlue(0,0,205)" 19 "Blue(0,0,255)" 18 "DarkSlateBlue(72,61,139)" 17 "SlateBlue(106,90,205)" 16 "MediumSlateBlue(123,104,238)" 15 "MediumPurple(147,112,219)" 14 "BlueViolet(138,43,226)" 13 "Indigo(75,0,130)" 12 "DarkOrchid(153,50,204)" 11 "DarkVoilet(148,0,211)" 10 "MediumOrchid(186,85,211)" 9 "DarkMagenta(139,0,139)" 8 "Magenta(255,0,255)" 7 "Violet(238,130,238)" 6 "Orchid(218,112,214)" 5 "MediumVioletRed(199,21,133)" 4 "DeepPink(255,20,147)" 3 "HotPink(255,105,180)" 2 "PaleVioletRed(219,112,147)" 1 "Crimson(220,20,60)" 0 "LightPink(255,182,193)";
VAL_ 535 User5AmbLightColor 63 "Red(255,0,0)" 62 "IndianRed(205,92,92)" 61 "LightCoral(240,128,128)" 60 "Tomato(255,99,71)" 59 "OrangeRed(255,69,0)" 58 "Coral(255,127,80)" 57 "LightSalmon(255,160,122)" 56 "DarkOrange(255,140,0)" 55 "Bisque(255,228,196)" 54 "NavajoWhite(255,222,173)" 53 "BlanchedAlmond(255,235,205)" 52 "Gold(255,215,0)" 51 "LemonChiffon(255,250,205)" 50 "Yellow(255,255,0)" 49 "LightYellow(255,255,224)" 48 "Ivory(255,255,240)" 47 "LightGoldenrodYellow(250,250,210)" 46 "Beige(245,245,220)" 45 "GreenYellow(173,255,47)" 44 "Chartreuse(127,255,0)" 43 "Lime(0,255,0)" 42 "LimeGreen(50,205,50)" 41 "PaleGreen(152,251,152)" 40 "LightGreen(144,238,144)" 39 "SeaGreen(46,139,87)" 38 "SpringGreen(60,179,113)" 37 "MediumSpringGreen(0,255,127)" 36 "MediumAquamarine(0,250,154)" 35 "Auqamarin(127,255,170)" 34 "MediumTurquoise(72,209,204)" 33 "DarkCyan(0,139,139)" 32 "DarkTurquoise(0,206,209)" 31 "Cyan(0,255,255)" 30 "PaleTurquoise(175,238,238)" 29 "DeepSkyBlue(0,191,255)" 28 "SkyBlue(135,206,235)" 27 "LightSkyBlue(135,206,250)" 26 "DoderBlue(30,144,255)" 25 "CornflowerBlue(100,149,237)" 24 "RoyalBlue(65,105,225)" 23 "Navy(0,0,128)" 22 "DarkBlue(0,0,139)" 21 "MidnightBlue(25,25,112)" 20 "MediumBlue(0,0,205)" 19 "Blue(0,0,255)" 18 "DarkSlateBlue(72,61,139)" 17 "SlateBlue(106,90,205)" 16 "MediumSlateBlue(123,104,238)" 15 "MediumPurple(147,112,219)" 14 "BlueViolet(138,43,226)" 13 "Indigo(75,0,130)" 12 "DarkOrchid(153,50,204)" 11 "DarkVoilet(148,0,211)" 10 "MediumOrchid(186,85,211)" 9 "DarkMagenta(139,0,139)" 8 "Magenta(255,0,255)" 7 "Violet(238,130,238)" 6 "Orchid(218,112,214)" 5 "MediumVioletRed(199,21,133)" 4 "DeepPink(255,20,147)" 3 "HotPink(255,105,180)" 2 "PaleVioletRed(219,112,147)" 1 "Crimson(220,20,60)" 0 "LightPink(255,182,193)";
VAL_ 535 User6AmbLightColor 63 "Red(255,0,0)" 62 "IndianRed(205,92,92)" 61 "LightCoral(240,128,128)" 60 "Tomato(255,99,71)" 59 "OrangeRed(255,69,0)" 58 "Coral(255,127,80)" 57 "LightSalmon(255,160,122)" 56 "DarkOrange(255,140,0)" 55 "Bisque(255,228,196)" 54 "NavajoWhite(255,222,173)" 53 "BlanchedAlmond(255,235,205)" 52 "Gold(255,215,0)" 51 "LemonChiffon(255,250,205)" 50 "Yellow(255,255,0)" 49 "LightYellow(255,255,224)" 48 "Ivory(255,255,240)" 47 "LightGoldenrodYellow(250,250,210)" 46 "Beige(245,245,220)" 45 "GreenYellow(173,255,47)" 44 "Chartreuse(127,255,0)" 43 "Lime(0,255,0)" 42 "LimeGreen(50,205,50)" 41 "PaleGreen(152,251,152)" 40 "LightGreen(144,238,144)" 39 "SeaGreen(46,139,87)" 38 "SpringGreen(60,179,113)" 37 "MediumSpringGreen(0,255,127)" 36 "MediumAquamarine(0,250,154)" 35 "Auqamarin(127,255,170)" 34 "MediumTurquoise(72,209,204)" 33 "DarkCyan(0,139,139)" 32 "DarkTurquoise(0,206,209)" 31 "Cyan(0,255,255)" 30 "PaleTurquoise(175,238,238)" 29 "DeepSkyBlue(0,191,255)" 28 "SkyBlue(135,206,235)" 27 "LightSkyBlue(135,206,250)" 26 "DoderBlue(30,144,255)" 25 "CornflowerBlue(100,149,237)" 24 "RoyalBlue(65,105,225)" 23 "Navy(0,0,128)" 22 "DarkBlue(0,0,139)" 21 "MidnightBlue(25,25,112)" 20 "MediumBlue(0,0,205)" 19 "Blue(0,0,255)" 18 "DarkSlateBlue(72,61,139)" 17 "SlateBlue(106,90,205)" 16 "MediumSlateBlue(123,104,238)" 15 "MediumPurple(147,112,219)" 14 "BlueViolet(138,43,226)" 13 "Indigo(75,0,130)" 12 "DarkOrchid(153,50,204)" 11 "DarkVoilet(148,0,211)" 10 "MediumOrchid(186,85,211)" 9 "DarkMagenta(139,0,139)" 8 "Magenta(255,0,255)" 7 "Violet(238,130,238)" 6 "Orchid(218,112,214)" 5 "MediumVioletRed(199,21,133)" 4 "DeepPink(255,20,147)" 3 "HotPink(255,105,180)" 2 "PaleVioletRed(219,112,147)" 1 "Crimson(220,20,60)" 0 "LightPink(255,182,193)";
VAL_ 535 User1IPAmbLightBrightness 101 "~0x7F Invalid" 100 "100%" 99 "99%" 98 "98%" 97 "97%" 96 "96%" 95 "95%" 94 "94%" 93 "93%" 92 "92%" 91 "91%" 90 "90%" 89 "89%" 88 "88%" 87 "87%" 86 "86%" 85 "85%" 84 "84%" 83 "83%" 82 "82%" 81 "81%" 80 "80%" 79 "79%" 78 "78%" 77 "77%" 76 "76%" 75 "75%" 74 "74%" 73 "73%" 72 "72%" 71 "71%" 70 "70%" 69 "69%" 68 "68%" 67 "67%" 66 "66%" 65 "65%" 64 "64%" 63 "63%" 62 "62%" 61 "61%" 60 "60%" 59 "59%" 58 "58%" 57 "57%" 56 "56%" 55 "55%" 54 "54%" 53 "53%" 52 "52%" 51 "51%" 50 "50%" 49 "49%" 48 "48%" 47 "47%" 46 "46%" 45 "45%" 44 "44%" 43 "43%" 42 "42%" 41 "41%" 40 "40%" 39 "39%" 38 "38%" 37 "37%" 36 "36%" 35 "35%" 34 "34%" 33 "33%" 32 "32%" 31 "31%" 30 "30%" 29 "29%" 28 "28%" 27 "27%" 26 "26%" 25 "25%" 24 "24%" 23 "23%" 22 "22%" 21 "21%" 20 "20%" 19 "19%" 18 "18%" 17 "17%" 16 "16%" 15 "15%" 14 "14%" 13 "13%" 12 "12%" 11 "11%" 10 "10%" 9 "9%" 8 "8%" 7 "7%" 6 "6%" 5 "5%" 4 "4%" 3 "3%" 2 "2%" 1 "1%" 0 "0%";
VAL_ 535 User2IPAmbLightBrightness 101 "~0x7F Invalid" 100 "100%" 99 "99%" 98 "98%" 97 "97%" 96 "96%" 95 "95%" 94 "94%" 93 "93%" 92 "92%" 91 "91%" 90 "90%" 89 "89%" 88 "88%" 87 "87%" 86 "86%" 85 "85%" 84 "84%" 83 "83%" 82 "82%" 81 "81%" 80 "80%" 79 "79%" 78 "78%" 77 "77%" 76 "76%" 75 "75%" 74 "74%" 73 "73%" 72 "72%" 71 "71%" 70 "70%" 69 "69%" 68 "68%" 67 "67%" 66 "66%" 65 "65%" 64 "64%" 63 "63%" 62 "62%" 61 "61%" 60 "60%" 59 "59%" 58 "58%" 57 "57%" 56 "56%" 55 "55%" 54 "54%" 53 "53%" 52 "52%" 51 "51%" 50 "50%" 49 "49%" 48 "48%" 47 "47%" 46 "46%" 45 "45%" 44 "44%" 43 "43%" 42 "42%" 41 "41%" 40 "40%" 39 "39%" 38 "38%" 37 "37%" 36 "36%" 35 "35%" 34 "34%" 33 "33%" 32 "32%" 31 "31%" 30 "30%" 29 "29%" 28 "28%" 27 "27%" 26 "26%" 25 "25%" 24 "24%" 23 "23%" 22 "22%" 21 "21%" 20 "20%" 19 "19%" 18 "18%" 17 "17%" 16 "16%" 15 "15%" 14 "14%" 13 "13%" 12 "12%" 11 "11%" 10 "10%" 9 "9%" 8 "8%" 7 "7%" 6 "6%" 5 "5%" 4 "4%" 3 "3%" 2 "2%" 1 "1%" 0 "0%";
VAL_ 535 User3IPAmbLightBrightness 101 "~0x7F Invalid" 100 "100%" 99 "99%" 98 "98%" 97 "97%" 96 "96%" 95 "95%" 94 "94%" 93 "93%" 92 "92%" 91 "91%" 90 "90%" 89 "89%" 88 "88%" 87 "87%" 86 "86%" 85 "85%" 84 "84%" 83 "83%" 82 "82%" 81 "81%" 80 "80%" 79 "79%" 78 "78%" 77 "77%" 76 "76%" 75 "75%" 74 "74%" 73 "73%" 72 "72%" 71 "71%" 70 "70%" 69 "69%" 68 "68%" 67 "67%" 66 "66%" 65 "65%" 64 "64%" 63 "63%" 62 "62%" 61 "61%" 60 "60%" 59 "59%" 58 "58%" 57 "57%" 56 "56%" 55 "55%" 54 "54%" 53 "53%" 52 "52%" 51 "51%" 50 "50%" 49 "49%" 48 "48%" 47 "47%" 46 "46%" 45 "45%" 44 "44%" 43 "43%" 42 "42%" 41 "41%" 40 "40%" 39 "39%" 38 "38%" 37 "37%" 36 "36%" 35 "35%" 34 "34%" 33 "33%" 32 "32%" 31 "31%" 30 "30%" 29 "29%" 28 "28%" 27 "27%" 26 "26%" 25 "25%" 24 "24%" 23 "23%" 22 "22%" 21 "21%" 20 "20%" 19 "19%" 18 "18%" 17 "17%" 16 "16%" 15 "15%" 14 "14%" 13 "13%" 12 "12%" 11 "11%" 10 "10%" 9 "9%" 8 "8%" 7 "7%" 6 "6%" 5 "5%" 4 "4%" 3 "3%" 2 "2%" 1 "1%" 0 "0%";
VAL_ 535 User4IPAmbLightBrightness 101 "~0x7F Invalid" 100 "100%" 99 "99%" 98 "98%" 97 "97%" 96 "96%" 95 "95%" 94 "94%" 93 "93%" 92 "92%" 91 "91%" 90 "90%" 89 "89%" 88 "88%" 87 "87%" 86 "86%" 85 "85%" 84 "84%" 83 "83%" 82 "82%" 81 "81%" 80 "80%" 79 "79%" 78 "78%" 77 "77%" 76 "76%" 75 "75%" 74 "74%" 73 "73%" 72 "72%" 71 "71%" 70 "70%" 69 "69%" 68 "68%" 67 "67%" 66 "66%" 65 "65%" 64 "64%" 63 "63%" 62 "62%" 61 "61%" 60 "60%" 59 "59%" 58 "58%" 57 "57%" 56 "56%" 55 "55%" 54 "54%" 53 "53%" 52 "52%" 51 "51%" 50 "50%" 49 "49%" 48 "48%" 47 "47%" 46 "46%" 45 "45%" 44 "44%" 43 "43%" 42 "42%" 41 "41%" 40 "40%" 39 "39%" 38 "38%" 37 "37%" 36 "36%" 35 "35%" 34 "34%" 33 "33%" 32 "32%" 31 "31%" 30 "30%" 29 "29%" 28 "28%" 27 "27%" 26 "26%" 25 "25%" 24 "24%" 23 "23%" 22 "22%" 21 "21%" 20 "20%" 19 "19%" 18 "18%" 17 "17%" 16 "16%" 15 "15%" 14 "14%" 13 "13%" 12 "12%" 11 "11%" 10 "10%" 9 "9%" 8 "8%" 7 "7%" 6 "6%" 5 "5%" 4 "4%" 3 "3%" 2 "2%" 1 "1%" 0 "0%";
VAL_ 535 User5IPAmbLightBrightness 101 "~0x7F Invalid" 100 "100%" 99 "99%" 98 "98%" 97 "97%" 96 "96%" 95 "95%" 94 "94%" 93 "93%" 92 "92%" 91 "91%" 90 "90%" 89 "89%" 88 "88%" 87 "87%" 86 "86%" 85 "85%" 84 "84%" 83 "83%" 82 "82%" 81 "81%" 80 "80%" 79 "79%" 78 "78%" 77 "77%" 76 "76%" 75 "75%" 74 "74%" 73 "73%" 72 "72%" 71 "71%" 70 "70%" 69 "69%" 68 "68%" 67 "67%" 66 "66%" 65 "65%" 64 "64%" 63 "63%" 62 "62%" 61 "61%" 60 "60%" 59 "59%" 58 "58%" 57 "57%" 56 "56%" 55 "55%" 54 "54%" 53 "53%" 52 "52%" 51 "51%" 50 "50%" 49 "49%" 48 "48%" 47 "47%" 46 "46%" 45 "45%" 44 "44%" 43 "43%" 42 "42%" 41 "41%" 40 "40%" 39 "39%" 38 "38%" 37 "37%" 36 "36%" 35 "35%" 34 "34%" 33 "33%" 32 "32%" 31 "31%" 30 "30%" 29 "29%" 28 "28%" 27 "27%" 26 "26%" 25 "25%" 24 "24%" 23 "23%" 22 "22%" 21 "21%" 20 "20%" 19 "19%" 18 "18%" 17 "17%" 16 "16%" 15 "15%" 14 "14%" 13 "13%" 12 "12%" 11 "11%" 10 "10%" 9 "9%" 8 "8%" 7 "7%" 6 "6%" 5 "5%" 4 "4%" 3 "3%" 2 "2%" 1 "1%" 0 "0%";
VAL_ 535 User6IPAmbLightBrightness 101 "~0x7F Invalid" 100 "100%" 99 "99%" 98 "98%" 97 "97%" 96 "96%" 95 "95%" 94 "94%" 93 "93%" 92 "92%" 91 "91%" 90 "90%" 89 "89%" 88 "88%" 87 "87%" 86 "86%" 85 "85%" 84 "84%" 83 "83%" 82 "82%" 81 "81%" 80 "80%" 79 "79%" 78 "78%" 77 "77%" 76 "76%" 75 "75%" 74 "74%" 73 "73%" 72 "72%" 71 "71%" 70 "70%" 69 "69%" 68 "68%" 67 "67%" 66 "66%" 65 "65%" 64 "64%" 63 "63%" 62 "62%" 61 "61%" 60 "60%" 59 "59%" 58 "58%" 57 "57%" 56 "56%" 55 "55%" 54 "54%" 53 "53%" 52 "52%" 51 "51%" 50 "50%" 49 "49%" 48 "48%" 47 "47%" 46 "46%" 45 "45%" 44 "44%" 43 "43%" 42 "42%" 41 "41%" 40 "40%" 39 "39%" 38 "38%" 37 "37%" 36 "36%" 35 "35%" 34 "34%" 33 "33%" 32 "32%" 31 "31%" 30 "30%" 29 "29%" 28 "28%" 27 "27%" 26 "26%" 25 "25%" 24 "24%" 23 "23%" 22 "22%" 21 "21%" 20 "20%" 19 "19%" 18 "18%" 17 "17%" 16 "16%" 15 "15%" 14 "14%" 13 "13%" 12 "12%" 11 "11%" 10 "10%" 9 "9%" 8 "8%" 7 "7%" 6 "6%" 5 "5%" 4 "4%" 3 "3%" 2 "2%" 1 "1%" 0 "0%";
VAL_ 535 User1DrAmbLightBrightness 101 "~0x7F Invalid" 100 "100%" 99 "99%" 98 "98%" 97 "97%" 96 "96%" 95 "95%" 94 "94%" 93 "93%" 92 "92%" 91 "91%" 90 "90%" 89 "89%" 88 "88%" 87 "87%" 86 "86%" 85 "85%" 84 "84%" 83 "83%" 82 "82%" 81 "81%" 80 "80%" 79 "79%" 78 "78%" 77 "77%" 76 "76%" 75 "75%" 74 "74%" 73 "73%" 72 "72%" 71 "71%" 70 "70%" 69 "69%" 68 "68%" 67 "67%" 66 "66%" 65 "65%" 64 "64%" 63 "63%" 62 "62%" 61 "61%" 60 "60%" 59 "59%" 58 "58%" 57 "57%" 56 "56%" 55 "55%" 54 "54%" 53 "53%" 52 "52%" 51 "51%" 50 "50%" 49 "49%" 48 "48%" 47 "47%" 46 "46%" 45 "45%" 44 "44%" 43 "43%" 42 "42%" 41 "41%" 40 "40%" 39 "39%" 38 "38%" 37 "37%" 36 "36%" 35 "35%" 34 "34%" 33 "33%" 32 "32%" 31 "31%" 30 "30%" 29 "29%" 28 "28%" 27 "27%" 26 "26%" 25 "25%" 24 "24%" 23 "23%" 22 "22%" 21 "21%" 20 "20%" 19 "19%" 18 "18%" 17 "17%" 16 "16%" 15 "15%" 14 "14%" 13 "13%" 12 "12%" 11 "11%" 10 "10%" 9 "9%" 8 "8%" 7 "7%" 6 "6%" 5 "5%" 4 "4%" 3 "3%" 2 "2%" 1 "1%" 0 "0%";
VAL_ 535 User2DrAmbLightBrightness 101 "~0x7F Invalid" 100 "100%" 99 "99%" 98 "98%" 97 "97%" 96 "96%" 95 "95%" 94 "94%" 93 "93%" 92 "92%" 91 "91%" 90 "90%" 89 "89%" 88 "88%" 87 "87%" 86 "86%" 85 "85%" 84 "84%" 83 "83%" 82 "82%" 81 "81%" 80 "80%" 79 "79%" 78 "78%" 77 "77%" 76 "76%" 75 "75%" 74 "74%" 73 "73%" 72 "72%" 71 "71%" 70 "70%" 69 "69%" 68 "68%" 67 "67%" 66 "66%" 65 "65%" 64 "64%" 63 "63%" 62 "62%" 61 "61%" 60 "60%" 59 "59%" 58 "58%" 57 "57%" 56 "56%" 55 "55%" 54 "54%" 53 "53%" 52 "52%" 51 "51%" 50 "50%" 49 "49%" 48 "48%" 47 "47%" 46 "46%" 45 "45%" 44 "44%" 43 "43%" 42 "42%" 41 "41%" 40 "40%" 39 "39%" 38 "38%" 37 "37%" 36 "36%" 35 "35%" 34 "34%" 33 "33%" 32 "32%" 31 "31%" 30 "30%" 29 "29%" 28 "28%" 27 "27%" 26 "26%" 25 "25%" 24 "24%" 23 "23%" 22 "22%" 21 "21%" 20 "20%" 19 "19%" 18 "18%" 17 "17%" 16 "16%" 15 "15%" 14 "14%" 13 "13%" 12 "12%" 11 "11%" 10 "10%" 9 "9%" 8 "8%" 7 "7%" 6 "6%" 5 "5%" 4 "4%" 3 "3%" 2 "2%" 1 "1%" 0 "0%";
VAL_ 535 User3DrAmbLightBrightness 101 "~0x7F Invalid" 100 "100%" 99 "99%" 98 "98%" 97 "97%" 96 "96%" 95 "95%" 94 "94%" 93 "93%" 92 "92%" 91 "91%" 90 "90%" 89 "89%" 88 "88%" 87 "87%" 86 "86%" 85 "85%" 84 "84%" 83 "83%" 82 "82%" 81 "81%" 80 "80%" 79 "79%" 78 "78%" 77 "77%" 76 "76%" 75 "75%" 74 "74%" 73 "73%" 72 "72%" 71 "71%" 70 "70%" 69 "69%" 68 "68%" 67 "67%" 66 "66%" 65 "65%" 64 "64%" 63 "63%" 62 "62%" 61 "61%" 60 "60%" 59 "59%" 58 "58%" 57 "57%" 56 "56%" 55 "55%" 54 "54%" 53 "53%" 52 "52%" 51 "51%" 50 "50%" 49 "49%" 48 "48%" 47 "47%" 46 "46%" 45 "45%" 44 "44%" 43 "43%" 42 "42%" 41 "41%" 40 "40%" 39 "39%" 38 "38%" 37 "37%" 36 "36%" 35 "35%" 34 "34%" 33 "33%" 32 "32%" 31 "31%" 30 "30%" 29 "29%" 28 "28%" 27 "27%" 26 "26%" 25 "25%" 24 "24%" 23 "23%" 22 "22%" 21 "21%" 20 "20%" 19 "19%" 18 "18%" 17 "17%" 16 "16%" 15 "15%" 14 "14%" 13 "13%" 12 "12%" 11 "11%" 10 "10%" 9 "9%" 8 "8%" 7 "7%" 6 "6%" 5 "5%" 4 "4%" 3 "3%" 2 "2%" 1 "1%" 0 "0%";
VAL_ 535 LampPwr 1 "ON" 0 "OFF";
VAL_ 535 User4DrAmbLightBrightness 101 "~0x7F Invalid" 100 "100%" 99 "99%" 98 "98%" 97 "97%" 96 "96%" 95 "95%" 94 "94%" 93 "93%" 92 "92%" 91 "91%" 90 "90%" 89 "89%" 88 "88%" 87 "87%" 86 "86%" 85 "85%" 84 "84%" 83 "83%" 82 "82%" 81 "81%" 80 "80%" 79 "79%" 78 "78%" 77 "77%" 76 "76%" 75 "75%" 74 "74%" 73 "73%" 72 "72%" 71 "71%" 70 "70%" 69 "69%" 68 "68%" 67 "67%" 66 "66%" 65 "65%" 64 "64%" 63 "63%" 62 "62%" 61 "61%" 60 "60%" 59 "59%" 58 "58%" 57 "57%" 56 "56%" 55 "55%" 54 "54%" 53 "53%" 52 "52%" 51 "51%" 50 "50%" 49 "49%" 48 "48%" 47 "47%" 46 "46%" 45 "45%" 44 "44%" 43 "43%" 42 "42%" 41 "41%" 40 "40%" 39 "39%" 38 "38%" 37 "37%" 36 "36%" 35 "35%" 34 "34%" 33 "33%" 32 "32%" 31 "31%" 30 "30%" 29 "29%" 28 "28%" 27 "27%" 26 "26%" 25 "25%" 24 "24%" 23 "23%" 22 "22%" 21 "21%" 20 "20%" 19 "19%" 18 "18%" 17 "17%" 16 "16%" 15 "15%" 14 "14%" 13 "13%" 12 "12%" 11 "11%" 10 "10%" 9 "9%" 8 "8%" 7 "7%" 6 "6%" 5 "5%" 4 "4%" 3 "3%" 2 "2%" 1 "1%" 0 "0%";
VAL_ 535 AmbLightBreath1 1 "ON" 0 "OFF";
VAL_ 535 User5DrAmbLightBrightness 101 "~0x7F Invalid" 100 "100%" 99 "99%" 98 "98%" 97 "97%" 96 "96%" 95 "95%" 94 "94%" 93 "93%" 92 "92%" 91 "91%" 90 "90%" 89 "89%" 88 "88%" 87 "87%" 86 "86%" 85 "85%" 84 "84%" 83 "83%" 82 "82%" 81 "81%" 80 "80%" 79 "79%" 78 "78%" 77 "77%" 76 "76%" 75 "75%" 74 "74%" 73 "73%" 72 "72%" 71 "71%" 70 "70%" 69 "69%" 68 "68%" 67 "67%" 66 "66%" 65 "65%" 64 "64%" 63 "63%" 62 "62%" 61 "61%" 60 "60%" 59 "59%" 58 "58%" 57 "57%" 56 "56%" 55 "55%" 54 "54%" 53 "53%" 52 "52%" 51 "51%" 50 "50%" 49 "49%" 48 "48%" 47 "47%" 46 "46%" 45 "45%" 44 "44%" 43 "43%" 42 "42%" 41 "41%" 40 "40%" 39 "39%" 38 "38%" 37 "37%" 36 "36%" 35 "35%" 34 "34%" 33 "33%" 32 "32%" 31 "31%" 30 "30%" 29 "29%" 28 "28%" 27 "27%" 26 "26%" 25 "25%" 24 "24%" 23 "23%" 22 "22%" 21 "21%" 20 "20%" 19 "19%" 18 "18%" 17 "17%" 16 "16%" 15 "15%" 14 "14%" 13 "13%" 12 "12%" 11 "11%" 10 "10%" 9 "9%" 8 "8%" 7 "7%" 6 "6%" 5 "5%" 4 "4%" 3 "3%" 2 "2%" 1 "1%" 0 "0%";
VAL_ 535 AmbLightBreath2 1 "ON" 0 "OFF";
VAL_ 535 User6DrAmbLightBrightness 101 "~0x7F Invalid" 100 "100%" 99 "99%" 98 "98%" 97 "97%" 96 "96%" 95 "95%" 94 "94%" 93 "93%" 92 "92%" 91 "91%" 90 "90%" 89 "89%" 88 "88%" 87 "87%" 86 "86%" 85 "85%" 84 "84%" 83 "83%" 82 "82%" 81 "81%" 80 "80%" 79 "79%" 78 "78%" 77 "77%" 76 "76%" 75 "75%" 74 "74%" 73 "73%" 72 "72%" 71 "71%" 70 "70%" 69 "69%" 68 "68%" 67 "67%" 66 "66%" 65 "65%" 64 "64%" 63 "63%" 62 "62%" 61 "61%" 60 "60%" 59 "59%" 58 "58%" 57 "57%" 56 "56%" 55 "55%" 54 "54%" 53 "53%" 52 "52%" 51 "51%" 50 "50%" 49 "49%" 48 "48%" 47 "47%" 46 "46%" 45 "45%" 44 "44%" 43 "43%" 42 "42%" 41 "41%" 40 "40%" 39 "39%" 38 "38%" 37 "37%" 36 "36%" 35 "35%" 34 "34%" 33 "33%" 32 "32%" 31 "31%" 30 "30%" 29 "29%" 28 "28%" 27 "27%" 26 "26%" 25 "25%" 24 "24%" 23 "23%" 22 "22%" 21 "21%" 20 "20%" 19 "19%" 18 "18%" 17 "17%" 16 "16%" 15 "15%" 14 "14%" 13 "13%" 12 "12%" 11 "11%" 10 "10%" 9 "9%" 8 "8%" 7 "7%" 6 "6%" 5 "5%" 4 "4%" 3 "3%" 2 "2%" 1 "1%" 0 "0%";
VAL_ 535 AmbLightBreath3 1 "ON" 0 "OFF";
VAL_ 547 FrntPTCBusLineHiV 1001 "~0x3FF   Invalid";
VAL_ 547 FrntPTCRiBusLineC 255 "Invalid";
VAL_ 547 FrntPTCLeBusLineC 255 "Invalid";
VAL_ 547 FrntPTCPCBT 255 "Invalid";
VAL_ 547 FrntPTCRiIGBTT 255 "Invalid";
VAL_ 547 FrntPTCLeIGBTT 255 "Invalid";
VAL_ 547 FrntPTCRiActHeatPwr 255 "Invalid" 201 "~ 0xFE Invalid";
VAL_ 547 FrntPTCLeActHeatPwr 255 "Invalid" 201 "~ 0xFE Invalid";
VAL_ 547 FrntPTCRiCoreT 255 "Invalid";
VAL_ 547 FrntPTCLeCoreT 255 "Invalid";
VAL_ 547 FrntPTCRearLeIGBTShoCFlt 1 "Failure" 0 "Normal";
VAL_ 547 FrntPTCRearRiIGBTShoCFlt 1 "Failure" 0 "Normal";
VAL_ 547 FrntPTCRearRiOpentCircFlt 1 "Failure" 0 "Normal";
VAL_ 547 FrntPTCRearRiOverAFlt 1 "Failure" 0 "Normal";
VAL_ 547 FrntPTCRearLeCoreTSnsrFlt 1 "Failure" 0 "Normal";
VAL_ 547 FrntPTCRearRiCoreTSnsrFlt 1 "Failure" 0 "Normal";
VAL_ 547 FrntPTCRearLeCoreOverTFlt 1 "Failure" 0 "Normal";
VAL_ 547 FrntPTCRearRiCoreOverTFlt 1 "Failure" 0 "Normal";
VAL_ 547 FrntPTCRearLeOpentCircFlt 1 "Failure" 0 "Normal";
VAL_ 547 FrntPTCRearLeOverAFlt 1 "Failure" 0 "Normal";
VAL_ 547 FrntPTCRiIGBTOverTFlt 1 "Failure" 0 "Normal";
VAL_ 547 FrntPTCLeIGBTOverTFlt 1 "Failure" 0 "Normal";
VAL_ 547 FrntPTCRiIGBTTSnsrFlt 1 "Failure" 0 "Normal";
VAL_ 547 FrntPTCLeIGBTTSnsrFlt 1 "Failure" 0 "Normal";
VAL_ 547 FrntPTCComFlt 1 "Failure" 0 "Normal";
VAL_ 547 FrntPTCPCBOverTFlt 1 "Failure" 0 "Normal";
VAL_ 547 FrntPTCPCBTSnsrFlt 1 "Failure" 0 "Normal";
VAL_ 547 FrntPTCRiOpentCircFlt 1 "Failure" 0 "Normal";
VAL_ 547 FrntPTCLeOpentCircFlt 1 "Failure" 0 "Normal";
VAL_ 547 FrntPTCRiIGBTShoCircFlt 1 "Failure" 0 "Normal";
VAL_ 547 FrntPTCLeIGBTShoCircFlt 1 "Failure" 0 "Normal";
VAL_ 547 FrntPTCRiCoreOverTFlt 1 "Failure" 0 "Normal";
VAL_ 547 FrntPTCLeCoreOverTFlt 1 "Failure" 0 "Normal";
VAL_ 547 FrntPTCRiCoreTSnsrFlt 1 "Failure" 0 "Normal";
VAL_ 547 FrntPTCLeCoreTSnsrFlt 1 "Failure" 0 "Normal";
VAL_ 547 FrntPTCRiOverAFlt 1 "Failure" 0 "Normal";
VAL_ 547 FrntPTCLeOverAFlt 1 "Failure" 0 "Normal";
VAL_ 547 FrntPTCHVOverUFlt 1 "Failure" 0 "Normal";
VAL_ 547 FrntPTCHVUnderUFlt 1 "Failure" 0 "Normal";
VAL_ 547 FrntPTCLVOverUFlt 1 "Failure" 0 "Normal";
VAL_ 547 FrntPTCLVUnderUFlt 1 "Failure" 0 "Normal";
VAL_ 547 FrntPTCFltSt 3 "Degraded Failure" 2 "Permanent Failure" 1 "Temporary Failure" 0 "Normal";
VAL_ 547 FrntPTCSts 1 "ON" 0 "OFF";
VAL_ 550 DrLockSta 1 "Lock" 0 "Unlcok";
VAL_ 550 PsLockSta 1 "Lock" 0 "Unlcok";
VAL_ 550 RLLockSta 1 "Lock" 0 "Unlcok";
VAL_ 550 RRLockSta 1 "Lock" 0 "Unlcok";
VAL_ 550 AllLockSta 1 "Lock" 0 "Unlcok";
VAL_ 550 MIRROR_FOLD_SW 1 "Press" 0 "Release";
VAL_ 550 RWiperAS 1 "Not at Stop Position" 0 "Stop Position";
VAL_ 550 RWiperProtection 1 "In protection" 0 "Not in Protectio";
VAL_ 550 Wip_Speed 3 "High speed" 2 "Low speed" 1 "Intermittent" 0 "OFF";
VAL_ 550 CSW_RWipIntSw_Sta 3 "Invalid" 2 "Low" 1 "int" 0 "off";
VAL_ 550 CSW_DimSw 1 "On" 0 "Off";
VAL_ 550 BrakeLampFail 1 "Fail" 0 "Normal";
VAL_ 550 CSW_PassSW_Sta 1 "Press" 0 "Release";
VAL_ 550 RLS_Exist 1 "Exist" 0 "Not Exist";
VAL_ 550 CSW_FWasSw_Sta 3 "invalid" 2 "Mist" 1 "ON" 0 "OFF";
VAL_ 550 CSW_RWasSW_Sta 3 "invalid" 1 "Press" 0 "Release";
VAL_ 550 CSW_TurnSw_Sta 3 "invalid" 2 "Right" 1 "Left" 0 "OFF";
VAL_ 550 HornSW 1 "Press" 0 "Release";
VAL_ 550 CSW_FWipSw_Sta 7 "invalid" 3 "High" 2 "Low" 1 "Auto" 0 "OFF";
VAL_ 550 RLS_RainSnrWiperCmd 7 "Failure" 3 "High Speed" 2 "Low Speed" 0 "Off";
VAL_ 550 RLS_Lamp_Sta 1 "Lamps ON" 0 "Lamps OFF";
VAL_ 550 WiperSWPos 8 "wash mode" 4 "wiper in HS mode(manual)" 2 "wiper in LS mode(manual)" 1 "wiper in Auto mode" 16 "mist mode" 0 "wiper off";
VAL_ 550 CSW_resp_error 1 "Error" 0 "Normal";
VAL_ 550 AutoLightSW 1 "EnableAutolamps" 0 "DisableAutolamps";
VAL_ 550 WiperZeroPosSW 1 "Wiper is not in zero position" 0 "Wiper is in zero position";
VAL_ 550 RLS_RainSnrErr 1 "RS error" 0 "RS no error";
VAL_ 550 RLS_LightSnrErr 1 "LS error" 0 "LS no error";
VAL_ 550 RLS_LIN_Resp_Err 1 "Error" 0 "Normal";
VAL_ 552 CCV4_MoveEnable 1 "ReqMotorMove" 0 "NoReq";
VAL_ 552 CCV4_ReqMovePos 1 "Open Port 1 to Port 4, Port 2 to port 3" 0 "Open Port 1 to Port 2, Port 3 to port 4";
VAL_ 552 EWP1_Default_Operation_EWP_Rq 1 "Default Operation" 0 "Default Sleep";
VAL_ 552 EWP3_Default_Operation_EWP_Rq 1 "Default Operation" 0 "Default Sleep";
VAL_ 552 BDC_1_MoveEnable 1 "ReqMotorMove" 0 "NoReq";
VAL_ 552 EWP2_Default_Operation_EWP_Rq 1 "Default Operation" 0 "Default Sleep";
VAL_ 552 EXV_Cmd_Move_Enbl 1 "Move to Commanded Position" 0 "Ignore Commanded Position";
VAL_ 552 EXV2_Cmd_Move_Enbl 1 "Move to Commanded Position" 0 "Ignore Commanded Position";
VAL_ 552 EXV2_Cmd_Init_Rq 7 "not defined" 6 "not defined" 5 "not defined" 4 "not defined" 3 "not defined" 2 "waiting for Sequence to finish" 1 "start Init-Sequence" 0 "No Request";
VAL_ 552 EXV_Cmd_Init_Rq 7 "not defined" 6 "not defined" 5 "not defined" 4 "not defined" 3 "not defined" 2 "waiting for Sequence to finish" 1 "start Init-Sequence" 0 "No Request";
VAL_ 552 EWP1_RPM_Target_EWP_Rq 255 "Invalid" 254 "max speed rpm" 253 "max speed rpm" 252 "max speed rpm" 251 "max speed rpm" 250 "linearly changed from min speed to max speed" 249 "linearly changed from min speed to max speed" 248 "linearly changed from min speed to max speed" 247 "linearly changed from min speed to max speed" 246 "linearly changed from min speed to max speed" 245 "linearly changed from min speed to max speed" 244 "linearly changed from min speed to max speed" 243 "linearly changed from min speed to max speed" 242 "linearly changed from min speed to max speed" 241 "linearly changed from min speed to max speed" 240 "linearly changed from min speed to max speed" 239 "linearly changed from min speed to max speed" 238 "linearly changed from min speed to max speed" 237 "linearly changed from min speed to max speed" 236 "linearly changed from min speed to max speed" 235 "linearly changed from min speed to max speed" 234 "linearly changed from min speed to max speed" 233 "linearly changed from min speed to max speed" 232 "linearly changed from min speed to max speed" 231 "linearly changed from min speed to max speed" 230 "linearly changed from min speed to max speed" 229 "linearly changed from min speed to max speed" 228 "linearly changed from min speed to max speed" 227 "linearly changed from min speed to max speed" 226 "linearly changed from min speed to max speed" 225 "linearly changed from min speed to max speed" 224 "linearly changed from min speed to max speed" 223 "linearly changed from min speed to max speed" 222 "linearly changed from min speed to max speed" 221 "linearly changed from min speed to max speed" 220 "linearly changed from min speed to max speed" 219 "linearly changed from min speed to max speed" 218 "linearly changed from min speed to max speed" 217 "linearly changed from min speed to max speed" 216 "linearly changed from min speed to max speed" 215 "linearly changed from min speed to max speed" 214 "linearly changed from min speed to max speed" 213 "linearly changed from min speed to max speed" 212 "linearly changed from min speed to max speed" 211 "linearly changed from min speed to max speed" 210 "linearly changed from min speed to max speed" 209 "linearly changed from min speed to max speed" 208 "linearly changed from min speed to max speed" 207 "linearly changed from min speed to max speed" 206 "linearly changed from min speed to max speed" 205 "linearly changed from min speed to max speed" 204 "linearly changed from min speed to max speed" 203 "linearly changed from min speed to max speed" 202 "linearly changed from min speed to max speed" 201 "linearly changed from min speed to max speed" 200 "linearly changed from min speed to max speed" 199 "linearly changed from min speed to max speed" 198 "linearly changed from min speed to max speed" 197 "linearly changed from min speed to max speed" 196 "linearly changed from min speed to max speed" 195 "linearly changed from min speed to max speed" 194 "linearly changed from min speed to max speed" 193 "linearly changed from min speed to max speed" 192 "linearly changed from min speed to max speed" 191 "linearly changed from min speed to max speed" 190 "linearly changed from min speed to max speed" 189 "linearly changed from min speed to max speed" 188 "linearly changed from min speed to max speed" 187 "linearly changed from min speed to max speed" 186 "linearly changed from min speed to max speed" 185 "linearly changed from min speed to max speed" 184 "linearly changed from min speed to max speed" 183 "linearly changed from min speed to max speed" 182 "linearly changed from min speed to max speed" 181 "linearly changed from min speed to max speed" 180 "linearly changed from min speed to max speed" 179 "linearly changed from min speed to max speed" 178 "linearly changed from min speed to max speed" 177 "linearly changed from min speed to max speed" 176 "linearly changed from min speed to max speed" 175 "linearly changed from min speed to max speed" 174 "linearly changed from min speed to max speed" 173 "linearly changed from min speed to max speed" 172 "linearly changed from min speed to max speed" 171 "linearly changed from min speed to max speed" 170 "linearly changed from min speed to max speed" 169 "linearly changed from min speed to max speed" 168 "linearly changed from min speed to max speed" 167 "linearly changed from min speed to max speed" 166 "linearly changed from min speed to max speed" 165 "linearly changed from min speed to max speed" 164 "linearly changed from min speed to max speed" 163 "linearly changed from min speed to max speed" 162 "linearly changed from min speed to max speed" 161 "linearly changed from min speed to max speed" 160 "linearly changed from min speed to max speed" 159 "linearly changed from min speed to max speed" 158 "linearly changed from min speed to max speed" 157 "linearly changed from min speed to max speed" 156 "linearly changed from min speed to max speed" 155 "linearly changed from min speed to max speed" 154 "linearly changed from min speed to max speed" 153 "linearly changed from min speed to max speed" 152 "linearly changed from min speed to max speed" 151 "linearly changed from min speed to max speed" 150 "linearly changed from min speed to max speed" 149 "linearly changed from min speed to max speed" 148 "linearly changed from min speed to max speed" 147 "linearly changed from min speed to max speed" 146 "linearly changed from min speed to max speed" 145 "linearly changed from min speed to max speed" 144 "linearly changed from min speed to max speed" 143 "linearly changed from min speed to max speed" 142 "linearly changed from min speed to max speed" 141 "linearly changed from min speed to max speed" 140 "linearly changed from min speed to max speed" 139 "linearly changed from min speed to max speed" 138 "linearly changed from min speed to max speed" 137 "linearly changed from min speed to max speed" 136 "linearly changed from min speed to max speed" 135 "linearly changed from min speed to max speed" 134 "linearly changed from min speed to max speed" 133 "linearly changed from min speed to max speed" 132 "linearly changed from min speed to max speed" 131 "linearly changed from min speed to max speed" 130 "linearly changed from min speed to max speed" 129 "linearly changed from min speed to max speed" 128 "linearly changed from min speed to max speed" 127 "linearly changed from min speed to max speed" 126 "linearly changed from min speed to max speed" 125 "linearly changed from min speed to max speed" 124 "linearly changed from min speed to max speed" 123 "linearly changed from min speed to max speed" 122 "linearly changed from min speed to max speed" 121 "linearly changed from min speed to max speed" 120 "linearly changed from min speed to max speed" 119 "linearly changed from min speed to max speed" 118 "linearly changed from min speed to max speed" 117 "linearly changed from min speed to max speed" 116 "linearly changed from min speed to max speed" 115 "linearly changed from min speed to max speed" 114 "linearly changed from min speed to max speed" 113 "linearly changed from min speed to max speed" 112 "linearly changed from min speed to max speed" 111 "linearly changed from min speed to max speed" 110 "linearly changed from min speed to max speed" 109 "linearly changed from min speed to max speed" 108 "linearly changed from min speed to max speed" 107 "linearly changed from min speed to max speed" 106 "linearly changed from min speed to max speed" 105 "linearly changed from min speed to max speed" 104 "linearly changed from min speed to max speed" 103 "linearly changed from min speed to max speed" 102 "linearly changed from min speed to max speed" 101 "linearly changed from min speed to max speed" 100 "linearly changed from min speed to max speed" 99 "linearly changed from min speed to max speed" 98 "linearly changed from min speed to max speed" 97 "linearly changed from min speed to max speed" 96 "linearly changed from min speed to max speed" 95 "linearly changed from min speed to max speed" 94 "linearly changed from min speed to max speed" 93 "linearly changed from min speed to max speed" 92 "linearly changed from min speed to max speed" 91 "linearly changed from min speed to max speed" 90 "linearly changed from min speed to max speed" 89 "linearly changed from min speed to max speed" 88 "linearly changed from min speed to max speed" 87 "linearly changed from min speed to max speed" 86 "linearly changed from min speed to max speed" 85 "linearly changed from min speed to max speed" 84 "linearly changed from min speed to max speed" 83 "linearly changed from min speed to max speed" 82 "linearly changed from min speed to max speed" 81 "linearly changed from min speed to max speed" 80 "linearly changed from min speed to max speed" 79 "linearly changed from min speed to max speed" 78 "linearly changed from min speed to max speed" 77 "linearly changed from min speed to max speed" 76 "linearly changed from min speed to max speed" 75 "linearly changed from min speed to max speed" 74 "linearly changed from min speed to max speed" 73 "linearly changed from min speed to max speed" 72 "linearly changed from min speed to max speed" 71 "linearly changed from min speed to max speed" 70 "linearly changed from min speed to max speed" 69 "linearly changed from min speed to max speed" 68 "linearly changed from min speed to max speed" 67 "linearly changed from min speed to max speed" 66 "linearly changed from min speed to max speed" 65 "linearly changed from min speed to max speed" 64 "linearly changed from min speed to max speed" 63 "linearly changed from min speed to max speed" 62 "linearly changed from min speed to max speed" 61 "linearly changed from min speed to max speed" 60 "linearly changed from min speed to max speed" 59 "linearly changed from min speed to max speed" 58 "linearly changed from min speed to max speed" 57 "linearly changed from min speed to max speed" 56 "linearly changed from min speed to max speed" 55 "linearly changed from min speed to max speed" 54 "linearly changed from min speed to max speed" 53 "linearly changed from min speed to max speed" 52 "linearly changed from min speed to max speed" 51 "linearly changed from min speed to max speed" 50 "linearly changed from min speed to max speed" 49 "min speed rpm" 48 "min speed rpm" 47 "min speed rpm" 46 "min speed rpm" 45 "min speed rpm" 44 "min speed rpm" 43 "min speed rpm" 42 "min speed rpm" 41 "min speed rpm" 40 "min speed rpm" 39 "min speed rpm" 38 "min speed rpm" 37 "min speed rpm" 36 "min speed rpm" 35 "min speed rpm" 34 "min speed rpm" 33 "min speed rpm" 32 "min speed rpm" 31 "min speed rpm" 30 "min speed rpm" 29 "min speed rpm" 28 "min speed rpm" 27 "min speed rpm" 26 "min speed rpm" 25 "min speed rpm" 24 "min speed rpm" 23 "min speed rpm" 22 "min speed rpm" 21 "min speed rpm" 20 "min speed rpm" 19 "min speed rpm" 18 "min speed rpm" 17 "min speed rpm" 16 "min speed rpm" 15 "min speed rpm" 14 "min speed rpm" 13 "min speed rpm" 12 "min speed rpm" 11 "min speed rpm" 10 "min speed rpm" 9 "min speed rpm" 8 "min speed rpm" 7 "min speed rpm" 6 "min speed rpm" 5 "min speed rpm" 4 "min speed rpm" 3 "0 rpm" 2 "0 rpm" 1 "0 rpm" 0 "0 rpm";
VAL_ 552 EWP3_RPM_Target_EWP_Rq 255 "Invalid" 254 "max speed rpm" 253 "max speed rpm" 252 "max speed rpm" 251 "max speed rpm" 250 "linearly changed from min speed to max speed" 249 "linearly changed from min speed to max speed" 248 "linearly changed from min speed to max speed" 247 "linearly changed from min speed to max speed" 246 "linearly changed from min speed to max speed" 245 "linearly changed from min speed to max speed" 244 "linearly changed from min speed to max speed" 243 "linearly changed from min speed to max speed" 242 "linearly changed from min speed to max speed" 241 "linearly changed from min speed to max speed" 240 "linearly changed from min speed to max speed" 239 "linearly changed from min speed to max speed" 238 "linearly changed from min speed to max speed" 237 "linearly changed from min speed to max speed" 236 "linearly changed from min speed to max speed" 235 "linearly changed from min speed to max speed" 234 "linearly changed from min speed to max speed" 233 "linearly changed from min speed to max speed" 232 "linearly changed from min speed to max speed" 231 "linearly changed from min speed to max speed" 230 "linearly changed from min speed to max speed" 229 "linearly changed from min speed to max speed" 228 "linearly changed from min speed to max speed" 227 "linearly changed from min speed to max speed" 226 "linearly changed from min speed to max speed" 225 "linearly changed from min speed to max speed" 224 "linearly changed from min speed to max speed" 223 "linearly changed from min speed to max speed" 222 "linearly changed from min speed to max speed" 221 "linearly changed from min speed to max speed" 220 "linearly changed from min speed to max speed" 219 "linearly changed from min speed to max speed" 218 "linearly changed from min speed to max speed" 217 "linearly changed from min speed to max speed" 216 "linearly changed from min speed to max speed" 215 "linearly changed from min speed to max speed" 214 "linearly changed from min speed to max speed" 213 "linearly changed from min speed to max speed" 212 "linearly changed from min speed to max speed" 211 "linearly changed from min speed to max speed" 210 "linearly changed from min speed to max speed" 209 "linearly changed from min speed to max speed" 208 "linearly changed from min speed to max speed" 207 "linearly changed from min speed to max speed" 206 "linearly changed from min speed to max speed" 205 "linearly changed from min speed to max speed" 204 "linearly changed from min speed to max speed" 203 "linearly changed from min speed to max speed" 202 "linearly changed from min speed to max speed" 201 "linearly changed from min speed to max speed" 200 "linearly changed from min speed to max speed" 199 "linearly changed from min speed to max speed" 198 "linearly changed from min speed to max speed" 197 "linearly changed from min speed to max speed" 196 "linearly changed from min speed to max speed" 195 "linearly changed from min speed to max speed" 194 "linearly changed from min speed to max speed" 193 "linearly changed from min speed to max speed" 192 "linearly changed from min speed to max speed" 191 "linearly changed from min speed to max speed" 190 "linearly changed from min speed to max speed" 189 "linearly changed from min speed to max speed" 188 "linearly changed from min speed to max speed" 187 "linearly changed from min speed to max speed" 186 "linearly changed from min speed to max speed" 185 "linearly changed from min speed to max speed" 184 "linearly changed from min speed to max speed" 183 "linearly changed from min speed to max speed" 182 "linearly changed from min speed to max speed" 181 "linearly changed from min speed to max speed" 180 "linearly changed from min speed to max speed" 179 "linearly changed from min speed to max speed" 178 "linearly changed from min speed to max speed" 177 "linearly changed from min speed to max speed" 176 "linearly changed from min speed to max speed" 175 "linearly changed from min speed to max speed" 174 "linearly changed from min speed to max speed" 173 "linearly changed from min speed to max speed" 172 "linearly changed from min speed to max speed" 171 "linearly changed from min speed to max speed" 170 "linearly changed from min speed to max speed" 169 "linearly changed from min speed to max speed" 168 "linearly changed from min speed to max speed" 167 "linearly changed from min speed to max speed" 166 "linearly changed from min speed to max speed" 165 "linearly changed from min speed to max speed" 164 "linearly changed from min speed to max speed" 163 "linearly changed from min speed to max speed" 162 "linearly changed from min speed to max speed" 161 "linearly changed from min speed to max speed" 160 "linearly changed from min speed to max speed" 159 "linearly changed from min speed to max speed" 158 "linearly changed from min speed to max speed" 157 "linearly changed from min speed to max speed" 156 "linearly changed from min speed to max speed" 155 "linearly changed from min speed to max speed" 154 "linearly changed from min speed to max speed" 153 "linearly changed from min speed to max speed" 152 "linearly changed from min speed to max speed" 151 "linearly changed from min speed to max speed" 150 "linearly changed from min speed to max speed" 149 "linearly changed from min speed to max speed" 148 "linearly changed from min speed to max speed" 147 "linearly changed from min speed to max speed" 146 "linearly changed from min speed to max speed" 145 "linearly changed from min speed to max speed" 144 "linearly changed from min speed to max speed" 143 "linearly changed from min speed to max speed" 142 "linearly changed from min speed to max speed" 141 "linearly changed from min speed to max speed" 140 "linearly changed from min speed to max speed" 139 "linearly changed from min speed to max speed" 138 "linearly changed from min speed to max speed" 137 "linearly changed from min speed to max speed" 136 "linearly changed from min speed to max speed" 135 "linearly changed from min speed to max speed" 134 "linearly changed from min speed to max speed" 133 "linearly changed from min speed to max speed" 132 "linearly changed from min speed to max speed" 131 "linearly changed from min speed to max speed" 130 "linearly changed from min speed to max speed" 129 "linearly changed from min speed to max speed" 128 "linearly changed from min speed to max speed" 127 "linearly changed from min speed to max speed" 126 "linearly changed from min speed to max speed" 125 "linearly changed from min speed to max speed" 124 "linearly changed from min speed to max speed" 123 "linearly changed from min speed to max speed" 122 "linearly changed from min speed to max speed" 121 "linearly changed from min speed to max speed" 120 "linearly changed from min speed to max speed" 119 "linearly changed from min speed to max speed" 118 "linearly changed from min speed to max speed" 117 "linearly changed from min speed to max speed" 116 "linearly changed from min speed to max speed" 115 "linearly changed from min speed to max speed" 114 "linearly changed from min speed to max speed" 113 "linearly changed from min speed to max speed" 112 "linearly changed from min speed to max speed" 111 "linearly changed from min speed to max speed" 110 "linearly changed from min speed to max speed" 109 "linearly changed from min speed to max speed" 108 "linearly changed from min speed to max speed" 107 "linearly changed from min speed to max speed" 106 "linearly changed from min speed to max speed" 105 "linearly changed from min speed to max speed" 104 "linearly changed from min speed to max speed" 103 "linearly changed from min speed to max speed" 102 "linearly changed from min speed to max speed" 101 "linearly changed from min speed to max speed" 100 "linearly changed from min speed to max speed" 99 "linearly changed from min speed to max speed" 98 "linearly changed from min speed to max speed" 97 "linearly changed from min speed to max speed" 96 "linearly changed from min speed to max speed" 95 "linearly changed from min speed to max speed" 94 "linearly changed from min speed to max speed" 93 "linearly changed from min speed to max speed" 92 "linearly changed from min speed to max speed" 91 "linearly changed from min speed to max speed" 90 "linearly changed from min speed to max speed" 89 "linearly changed from min speed to max speed" 88 "linearly changed from min speed to max speed" 87 "linearly changed from min speed to max speed" 86 "linearly changed from min speed to max speed" 85 "linearly changed from min speed to max speed" 84 "linearly changed from min speed to max speed" 83 "linearly changed from min speed to max speed" 82 "linearly changed from min speed to max speed" 81 "linearly changed from min speed to max speed" 80 "linearly changed from min speed to max speed" 79 "linearly changed from min speed to max speed" 78 "linearly changed from min speed to max speed" 77 "linearly changed from min speed to max speed" 76 "linearly changed from min speed to max speed" 75 "linearly changed from min speed to max speed" 74 "linearly changed from min speed to max speed" 73 "linearly changed from min speed to max speed" 72 "linearly changed from min speed to max speed" 71 "linearly changed from min speed to max speed" 70 "linearly changed from min speed to max speed" 69 "linearly changed from min speed to max speed" 68 "linearly changed from min speed to max speed" 67 "linearly changed from min speed to max speed" 66 "linearly changed from min speed to max speed" 65 "linearly changed from min speed to max speed" 64 "linearly changed from min speed to max speed" 63 "linearly changed from min speed to max speed" 62 "linearly changed from min speed to max speed" 61 "linearly changed from min speed to max speed" 60 "linearly changed from min speed to max speed" 59 "linearly changed from min speed to max speed" 58 "linearly changed from min speed to max speed" 57 "linearly changed from min speed to max speed" 56 "linearly changed from min speed to max speed" 55 "linearly changed from min speed to max speed" 54 "linearly changed from min speed to max speed" 53 "linearly changed from min speed to max speed" 52 "linearly changed from min speed to max speed" 51 "linearly changed from min speed to max speed" 50 "linearly changed from min speed to max speed" 49 "min speed rpm" 48 "min speed rpm" 47 "min speed rpm" 46 "min speed rpm" 45 "min speed rpm" 44 "min speed rpm" 43 "min speed rpm" 42 "min speed rpm" 41 "min speed rpm" 40 "min speed rpm" 39 "min speed rpm" 38 "min speed rpm" 37 "min speed rpm" 36 "min speed rpm" 35 "min speed rpm" 34 "min speed rpm" 33 "min speed rpm" 32 "min speed rpm" 31 "min speed rpm" 30 "min speed rpm" 29 "min speed rpm" 28 "min speed rpm" 27 "min speed rpm" 26 "min speed rpm" 25 "min speed rpm" 24 "min speed rpm" 23 "min speed rpm" 22 "min speed rpm" 21 "min speed rpm" 20 "min speed rpm" 19 "min speed rpm" 18 "min speed rpm" 17 "min speed rpm" 16 "min speed rpm" 15 "min speed rpm" 14 "min speed rpm" 13 "min speed rpm" 12 "min speed rpm" 11 "min speed rpm" 10 "min speed rpm" 9 "min speed rpm" 8 "min speed rpm" 7 "min speed rpm" 6 "min speed rpm" 5 "min speed rpm" 4 "min speed rpm" 3 "0 rpm" 2 "0 rpm" 1 "0 rpm" 0 "0 rpm";
VAL_ 552 EWP2_RPM_Target_EWP_Rq 255 "Invalid" 254 "max speed rpm" 253 "max speed rpm" 252 "max speed rpm" 251 "max speed rpm" 250 "linearly changed from min speed to max speed" 249 "linearly changed from min speed to max speed" 248 "linearly changed from min speed to max speed" 247 "linearly changed from min speed to max speed" 246 "linearly changed from min speed to max speed" 245 "linearly changed from min speed to max speed" 244 "linearly changed from min speed to max speed" 243 "linearly changed from min speed to max speed" 242 "linearly changed from min speed to max speed" 241 "linearly changed from min speed to max speed" 240 "linearly changed from min speed to max speed" 239 "linearly changed from min speed to max speed" 238 "linearly changed from min speed to max speed" 237 "linearly changed from min speed to max speed" 236 "linearly changed from min speed to max speed" 235 "linearly changed from min speed to max speed" 234 "linearly changed from min speed to max speed" 233 "linearly changed from min speed to max speed" 232 "linearly changed from min speed to max speed" 231 "linearly changed from min speed to max speed" 230 "linearly changed from min speed to max speed" 229 "linearly changed from min speed to max speed" 228 "linearly changed from min speed to max speed" 227 "linearly changed from min speed to max speed" 226 "linearly changed from min speed to max speed" 225 "linearly changed from min speed to max speed" 224 "linearly changed from min speed to max speed" 223 "linearly changed from min speed to max speed" 222 "linearly changed from min speed to max speed" 221 "linearly changed from min speed to max speed" 220 "linearly changed from min speed to max speed" 219 "linearly changed from min speed to max speed" 218 "linearly changed from min speed to max speed" 217 "linearly changed from min speed to max speed" 216 "linearly changed from min speed to max speed" 215 "linearly changed from min speed to max speed" 214 "linearly changed from min speed to max speed" 213 "linearly changed from min speed to max speed" 212 "linearly changed from min speed to max speed" 211 "linearly changed from min speed to max speed" 210 "linearly changed from min speed to max speed" 209 "linearly changed from min speed to max speed" 208 "linearly changed from min speed to max speed" 207 "linearly changed from min speed to max speed" 206 "linearly changed from min speed to max speed" 205 "linearly changed from min speed to max speed" 204 "linearly changed from min speed to max speed" 203 "linearly changed from min speed to max speed" 202 "linearly changed from min speed to max speed" 201 "linearly changed from min speed to max speed" 200 "linearly changed from min speed to max speed" 199 "linearly changed from min speed to max speed" 198 "linearly changed from min speed to max speed" 197 "linearly changed from min speed to max speed" 196 "linearly changed from min speed to max speed" 195 "linearly changed from min speed to max speed" 194 "linearly changed from min speed to max speed" 193 "linearly changed from min speed to max speed" 192 "linearly changed from min speed to max speed" 191 "linearly changed from min speed to max speed" 190 "linearly changed from min speed to max speed" 189 "linearly changed from min speed to max speed" 188 "linearly changed from min speed to max speed" 187 "linearly changed from min speed to max speed" 186 "linearly changed from min speed to max speed" 185 "linearly changed from min speed to max speed" 184 "linearly changed from min speed to max speed" 183 "linearly changed from min speed to max speed" 182 "linearly changed from min speed to max speed" 181 "linearly changed from min speed to max speed" 180 "linearly changed from min speed to max speed" 179 "linearly changed from min speed to max speed" 178 "linearly changed from min speed to max speed" 177 "linearly changed from min speed to max speed" 176 "linearly changed from min speed to max speed" 175 "linearly changed from min speed to max speed" 174 "linearly changed from min speed to max speed" 173 "linearly changed from min speed to max speed" 172 "linearly changed from min speed to max speed" 171 "linearly changed from min speed to max speed" 170 "linearly changed from min speed to max speed" 169 "linearly changed from min speed to max speed" 168 "linearly changed from min speed to max speed" 167 "linearly changed from min speed to max speed" 166 "linearly changed from min speed to max speed" 165 "linearly changed from min speed to max speed" 164 "linearly changed from min speed to max speed" 163 "linearly changed from min speed to max speed" 162 "linearly changed from min speed to max speed" 161 "linearly changed from min speed to max speed" 160 "linearly changed from min speed to max speed" 159 "linearly changed from min speed to max speed" 158 "linearly changed from min speed to max speed" 157 "linearly changed from min speed to max speed" 156 "linearly changed from min speed to max speed" 155 "linearly changed from min speed to max speed" 154 "linearly changed from min speed to max speed" 153 "linearly changed from min speed to max speed" 152 "linearly changed from min speed to max speed" 151 "linearly changed from min speed to max speed" 150 "linearly changed from min speed to max speed" 149 "linearly changed from min speed to max speed" 148 "linearly changed from min speed to max speed" 147 "linearly changed from min speed to max speed" 146 "linearly changed from min speed to max speed" 145 "linearly changed from min speed to max speed" 144 "linearly changed from min speed to max speed" 143 "linearly changed from min speed to max speed" 142 "linearly changed from min speed to max speed" 141 "linearly changed from min speed to max speed" 140 "linearly changed from min speed to max speed" 139 "linearly changed from min speed to max speed" 138 "linearly changed from min speed to max speed" 137 "linearly changed from min speed to max speed" 136 "linearly changed from min speed to max speed" 135 "linearly changed from min speed to max speed" 134 "linearly changed from min speed to max speed" 133 "linearly changed from min speed to max speed" 132 "linearly changed from min speed to max speed" 131 "linearly changed from min speed to max speed" 130 "linearly changed from min speed to max speed" 129 "linearly changed from min speed to max speed" 128 "linearly changed from min speed to max speed" 127 "linearly changed from min speed to max speed" 126 "linearly changed from min speed to max speed" 125 "linearly changed from min speed to max speed" 124 "linearly changed from min speed to max speed" 123 "linearly changed from min speed to max speed" 122 "linearly changed from min speed to max speed" 121 "linearly changed from min speed to max speed" 120 "linearly changed from min speed to max speed" 119 "linearly changed from min speed to max speed" 118 "linearly changed from min speed to max speed" 117 "linearly changed from min speed to max speed" 116 "linearly changed from min speed to max speed" 115 "linearly changed from min speed to max speed" 114 "linearly changed from min speed to max speed" 113 "linearly changed from min speed to max speed" 112 "linearly changed from min speed to max speed" 111 "linearly changed from min speed to max speed" 110 "linearly changed from min speed to max speed" 109 "linearly changed from min speed to max speed" 108 "linearly changed from min speed to max speed" 107 "linearly changed from min speed to max speed" 106 "linearly changed from min speed to max speed" 105 "linearly changed from min speed to max speed" 104 "linearly changed from min speed to max speed" 103 "linearly changed from min speed to max speed" 102 "linearly changed from min speed to max speed" 101 "linearly changed from min speed to max speed" 100 "linearly changed from min speed to max speed" 99 "linearly changed from min speed to max speed" 98 "linearly changed from min speed to max speed" 97 "linearly changed from min speed to max speed" 96 "linearly changed from min speed to max speed" 95 "linearly changed from min speed to max speed" 94 "linearly changed from min speed to max speed" 93 "linearly changed from min speed to max speed" 92 "linearly changed from min speed to max speed" 91 "linearly changed from min speed to max speed" 90 "linearly changed from min speed to max speed" 89 "linearly changed from min speed to max speed" 88 "linearly changed from min speed to max speed" 87 "linearly changed from min speed to max speed" 86 "linearly changed from min speed to max speed" 85 "linearly changed from min speed to max speed" 84 "linearly changed from min speed to max speed" 83 "linearly changed from min speed to max speed" 82 "linearly changed from min speed to max speed" 81 "linearly changed from min speed to max speed" 80 "linearly changed from min speed to max speed" 79 "linearly changed from min speed to max speed" 78 "linearly changed from min speed to max speed" 77 "linearly changed from min speed to max speed" 76 "linearly changed from min speed to max speed" 75 "linearly changed from min speed to max speed" 74 "linearly changed from min speed to max speed" 73 "linearly changed from min speed to max speed" 72 "linearly changed from min speed to max speed" 71 "linearly changed from min speed to max speed" 70 "linearly changed from min speed to max speed" 69 "linearly changed from min speed to max speed" 68 "linearly changed from min speed to max speed" 67 "linearly changed from min speed to max speed" 66 "linearly changed from min speed to max speed" 65 "linearly changed from min speed to max speed" 64 "linearly changed from min speed to max speed" 63 "linearly changed from min speed to max speed" 62 "linearly changed from min speed to max speed" 61 "linearly changed from min speed to max speed" 60 "linearly changed from min speed to max speed" 59 "linearly changed from min speed to max speed" 58 "linearly changed from min speed to max speed" 57 "linearly changed from min speed to max speed" 56 "linearly changed from min speed to max speed" 55 "linearly changed from min speed to max speed" 54 "linearly changed from min speed to max speed" 53 "linearly changed from min speed to max speed" 52 "linearly changed from min speed to max speed" 51 "linearly changed from min speed to max speed" 50 "linearly changed from min speed to max speed" 49 "min speed rpm" 48 "min speed rpm" 47 "min speed rpm" 46 "min speed rpm" 45 "min speed rpm" 44 "min speed rpm" 43 "min speed rpm" 42 "min speed rpm" 41 "min speed rpm" 40 "min speed rpm" 39 "min speed rpm" 38 "min speed rpm" 37 "min speed rpm" 36 "min speed rpm" 35 "min speed rpm" 34 "min speed rpm" 33 "min speed rpm" 32 "min speed rpm" 31 "min speed rpm" 30 "min speed rpm" 29 "min speed rpm" 28 "min speed rpm" 27 "min speed rpm" 26 "min speed rpm" 25 "min speed rpm" 24 "min speed rpm" 23 "min speed rpm" 22 "min speed rpm" 21 "min speed rpm" 20 "min speed rpm" 19 "min speed rpm" 18 "min speed rpm" 17 "min speed rpm" 16 "min speed rpm" 15 "min speed rpm" 14 "min speed rpm" 13 "min speed rpm" 12 "min speed rpm" 11 "min speed rpm" 10 "min speed rpm" 9 "min speed rpm" 8 "min speed rpm" 7 "min speed rpm" 6 "min speed rpm" 5 "min speed rpm" 4 "min speed rpm" 3 "0 rpm" 2 "0 rpm" 1 "0 rpm" 0 "0 rpm";
VAL_ 552 FWiperAS 1 "Not at Stop Position" 0 "Stop Position";
VAL_ 552 FWiperProtection 1 "In protection" 0 "Not in Protectio";
VAL_ 552 ChargeInletLockSta 1 "Lock" 0 "Unlock";
VAL_ 552 AGS_Position_Request 208 "78¢X" 240 "90¢X" 176 "66¢X" 144 "54¢X" 112 "42¢X" 80 "30¢X" 48 "18¢X" 16 "6¢X" 224 "84¢X" 192 "72¢X" 160 "60¢X" 128 "48¢X" 96 "36¢X" 64 "24¢X" 32 "12¢X" 0 "0¢X";
VAL_ 552 AGS_Calibration_Enabled 1 "CALIB_ENABLE" 0 "NO_CALIB";
VAL_ 552 AGS_LINResponse_Error 1 "ERROR" 0 "NO_ERROR";
VAL_ 552 AGS_Actuator_Blocked 1 "ERROR" 0 "NO_ERROR";
VAL_ 552 AGS_Actuator_Fault 1 "ERROR" 0 "NO_ERROR";
VAL_ 552 AGS_Calibration_Active 1 "Caliberation_Process_active" 0 "Caliberation_process_inactive";
VAL_ 552 AGS_Calibration_Indicated 1 "CALIBRATION_REQ" 0 "NO_CALIBRATION";
VAL_ 552 AGS_Electrical_Error 1 "ERROR" 0 "NO_ERROR";
VAL_ 552 AGS_Sensor_Error 1 "ERROR" 0 "NO_ERROR";
VAL_ 552 AGS_Temperature_Error 1 "ERROR" 0 "NO_ERROR";
VAL_ 552 AGS_Low_Voltage_Error 1 "ERROR" 0 "NO_Voltage_ERROR";
VAL_ 552 AGS_Actual_Position 240 "90^Deg" 208 "78^Deg" 176 "66^Deg" 144 "54^Deg" 112 "42^Deg" 80 "30^Deg" 48 "18^Deg" 16 "6^Deg" 224 "84^Deg" 192 "72^Deg" 160 "60^Deg" 128 "48^Deg" 96 "36^Deg" 64 "24^Deg" 32 "12^Deg" 0 "0^Deg";
VAL_ 553 EPS_Pwr_Consumpt_V 1 "Valid" 0 "Invalid";
VAL_ 553 EPS_VOL_V 1 "Valid" 0 "Invalid";
VAL_ 553 EPS_Temp_V 1 "Valid" 0 "Invalid";
VAL_ 553 EpasFailed 2 "Perm Faild" 1 "Temp Faild" 0 "Not Faild";
VAL_ 553 EPS_Pwr_Limit_V 1 "Valid" 0 "Invalid";
VAL_ 553 Steering_Torque_V 1 "Failed" 0 "Not Failed";
VAL_ 566 APS_Sta_System 4 "Remote Actived" 3 "Failed" 2 "Active" 1 "Enable" 0 "Disable";
VAL_ 566 APS_V_Rq_EPAS_Ctrl 1 "Valid" 0 "Invalid";
VAL_ 566 APS_Rq_EPAS_Ctrl 1 "Request on EPS Control" 0 "No Request on EPS Control";
VAL_ 568 APS_Req 3 "Standstill with EPB" 2 "Standstill with Brake Hold" 1 "Decel Control" 0 "No request";
VAL_ 568 SPTG_Sta 2 "enable" 1 "disable" 0 "OFF";
VAL_ 568 CAAS_Sta 3 "Active" 2 "enable" 1 "disable" 0 "OFF";
VAL_ 568 APS_DecReq_A 1 "Applicable" 0 "Not Applicable";
VAL_ 568 SPTGDet 1 "request" 0 "no request";
VAL_ 568 APSOpenPTG 1 "request" 0 "no request";
VAL_ 570 ADAS_SLIF_SpdLim 31 "80mph" 30 "75mph" 29 "70mph" 28 "65mph" 27 "60mph" 26 "55mph" 25 "50mph" 24 "45mph" 23 "40mph" 22 "35mph" 21 "30mph" 20 "25mph" 19 "20mph" 18 "15mph" 17 "10mph" 16 "160 km/h" 15 "150 km/h" 14 "140 km/h" 13 "130 km/h" 12 "120 km/h" 11 "110 km/h" 10 "100 km/h" 9 "90 km/h" 8 "80 km/h" 7 "70 km/h" 6 "60 km/h" 5 "50 km/h" 4 "40 km/h" 3 "30 km/h" 2 "20 km/h" 1 "10 km/h" 0 "No request";
VAL_ 570 Target_Type 4 "Truck" 3 "Two Wheel" 2 "Vehicle" 1 "Pedestrian" 0 "None";
VAL_ 570 ADAS_CAM_SpdLim 31 "80mph" 30 "75mph" 29 "70mph" 28 "65mph" 27 "60mph" 26 "55mph" 25 "50mph" 24 "45mph" 23 "40mph" 22 "35mph" 21 "30mph" 20 "25mph" 19 "20mph" 18 "15mph" 17 "10mph" 16 "160 km/h" 15 "150 km/h" 14 "140 km/h" 13 "130 km/h" 12 "120 km/h" 11 "110 km/h" 10 "100 km/h" 9 "90 km/h" 8 "80 km/h" 7 "70 km/h" 6 "60 km/h" 5 "50 km/h" 4 "40 km/h" 3 "30 km/h" 2 "20 km/h" 1 "10 km/h" 0 "No request";
VAL_ 570 ADAS_WarningMsg 15 "reserve" 14 "reserve" 13 "reserve" 12 "reserve" 11 "reserve" 10 "reserve" 9 "reserve" 8 "reserve" 7 "Takeover Request" 6 "Disable to Engage FSRA" 5 "FSRA Disengaged" 4 "Available to resume Acceleration Control" 3 "Object Disappeared" 2 "reserve" 1 "reserve" 0 "None";
VAL_ 570 ACC_TakeoverReq 1 "request" 0 "no request";
VAL_ 570 ACCSetSpeed_Disp 3 "Green" 2 "Grey" 1 "Dash Line" 0 "None";
VAL_ 570 TimeGapLevel 4 "Level 4" 3 "Level 3" 2 "Level 2" 1 "Level 1" 0 "Off";
VAL_ 570 ForceLowBeam 2 "Invalid" 1 "Force Low Beam" 0 "No Request";
VAL_ 570 ACC_ObjDstLvl 4 "Level 4" 3 "Level 3" 2 "Level 2" 1 "Level 1" 0 "None";
VAL_ 570 ADAS_ACC_Sta 6 "Disable" 5 "Error" 4 "Shut-off" 3 "Override" 2 "Active" 1 "Standby" 0 "Off";
VAL_ 570 ADAS_FltWrnReq 1 "Warning Request" 0 "No Warning";
VAL_ 570 ADAS_LDW_Sta 6 "Disable" 5 "Error" 4 "Right warning" 3 "Left warning" 2 "Active" 1 "Standby" 0 "Off";
VAL_ 570 LeftTurnLightReq 1 "Request" 0 "No Request";
VAL_ 570 ADAS_FCW_Sta 4 "Disable" 3 "Error" 2 "Active" 1 "Standby" 0 "Off";
VAL_ 570 RightTurnLightReq 1 "Request" 0 "No Request";
VAL_ 570 ADAS_AEB_Sta 4 "Disable" 3 "Error" 2 "Active" 1 "Standby" 0 "Off";
VAL_ 570 HazardWarningReq 1 "Request" 0 "No Request";
VAL_ 572 ADAS_LFC_Warn_Sound 1 "Warning Sound" 0 "OFF";
VAL_ 572 LVDA_ACCStatusInformation 1 "ACC is in stop-hold mode" 0 "Default";
VAL_ 572 LVDA_Warning 1 "Warning" 0 "No warning";
VAL_ 572 LVDA_Failinfo 1 "Fail" 0 "No fail";
VAL_ 572 LVDA_Mute_Sta 3 "Invalid" 2 "Mute" 1 "No Mute" 0 "Default";
VAL_ 572 LVDA_Disabled 1 "Disabled" 0 "Enabled";
VAL_ 572 ADAS_LFC_Hands_Off_Warning 3 "Automatic release warning" 2 "2nd Warning" 1 "1st Warning" 0 "OFF";
VAL_ 572 ADAS_FCW_Mute 1 "Mute" 0 "No Mute";
VAL_ 572 ADAS_LDW_Mute 1 "Mute" 0 "No Mute";
VAL_ 572 ADAS_ISA_Sta 3 "Disable" 2 "Error" 1 "Active" 0 "Off";
VAL_ 572 ADAS_SLIF_Sta 5 "Disable" 4 "Invalid" 3 "Temporary Unavailable" 2 "System Fail" 1 "Normal (Default)" 0 "OFF";
VAL_ 572 ADAS_LaneModeR 1 "Detected" 0 "Not detected";
VAL_ 572 ADAS_LaneModeL 1 "Detected" 0 "Not detected";
VAL_ 572 ADAS_LFC_Sta 5 "Disable" 4 "Error" 3 "Green Blinking" 2 "Green" 1 "White" 0 "OFF";
VAL_ 572 LKA_HOD_Sound_Warning 1 "Hands-off Warning" 0 "No Warning";
VAL_ 572 ADAS_LKA_Sta 6 "Disable" 5 "Error" 4 "Right Assist" 3 "Left Assist" 2 "Active" 1 "Standby" 0 "Off";
VAL_ 572 LKA_HOD_Display_Warning 1 "Hands-off Warning" 0 "No Warning";
VAL_ 581 Re_VehThdChkSta 7 "Check invalid" 6 "HVB SoC too low" 5 "Door or hood or tailgate open" 4 "Anti-theft not in arm" 3 "Vehicle not in steady state" 2 "HVB error" 1 "Gear position error" 0 "Check ok";
VAL_ 581 LowSOCWarn 1 "HV SOC low warning" 0 "Normal";
VAL_ 581 EDriveSysErr_ShifterErr 1 "Error" 0 "Normal";
VAL_ 581 LimphomeAct 1 "Active" 0 "Inactive";
VAL_ 581 EDriveSysErr_MCUErr 1 "Error" 0 "Normal";
VAL_ 581 EDriveSysErr_AccPedalErr 1 "Error" 0 "Normal";
VAL_ 581 EDriveSysErr_VCUErr 1 "Error" 0 "Normal";
VAL_ 581 LVSysErr_PwrOutpErr 1 "Error" 0 "Normal";
VAL_ 581 PwrStaErr 1 "Error" 0 "Normal";
VAL_ 581 HVSysErr_IsolationErr 1 "Error" 0 "Normal";
VAL_ 581 HVSysErr_PackErr 1 "Error" 0 "Normal";
VAL_ 581 HVSysErr_RelayErr 1 "Error" 0 "Normal";
VAL_ 659 DrSCPSysErrLmp 1 "Error" 0 "Normal";
VAL_ 659 RegenMode 7 "Invalid" 6 "One-Pedal" 5 "Level 5" 4 "Level 4" 3 "Level 3" 2 "Level 2" 1 "Level 1" 0 "Off";
VAL_ 659 Zone_Spd_Ctrl_Sta 1 "ON" 0 "OFF";
VAL_ 659 Zone_Spd_Ctrl_Mode 5 "invalid" 4 "ISA" 3 "LIM" 2 "CC" 1 "ACC" 0 "OFF";
VAL_ 809 CellType 2 "AB battery" 1 "NCM" 0 "LFP";
VAL_ 809 SOC_UseLimit 2 "12%, limited" 1 "6%, limited" 0 "3%, normal";
VAL_ 809 BMS_HVBattCellBalance_Sta 1 "Balance Enable" 0 "Balance Disable";
VAL_ 820 MainChrgRlyPosSta 3 "Error" 2 "Closed" 1 "Open" 0 "None";
VAL_ 820 MainChrgRlyNegSta 3 "Error" 2 "Closed" 1 "Open" 0 "None";
VAL_ 820 MainRlyNegSta 3 "Error" 2 "Closed" 1 "Open" 0 "None";
VAL_ 820 MainRlyPosSta 3 "Error" 2 "Closed" 1 "Open" 0 "None";
VAL_ 820 MainChrgRlyNegDriReq 3 "Error" 2 "Closed" 1 "Open" 0 "None";
VAL_ 820 MainChrgRlyPosDriReq 3 "Error" 2 "Closed" 1 "Open" 0 "None";
VAL_ 820 MainRlyNegDriReq 3 "Error" 2 "Closed" 1 "Open" 0 "None";
VAL_ 820 MainRlyPosDriReq 3 "Error" 2 "Closed" 1 "Open" 0 "None";
VAL_ 826 SWC_LKA_Sta 1 "Press" 0 "Release";
VAL_ 826 SWC_Undefined_Sta 1 "Press" 0 "Release";
VAL_ 826 SWC_VR_Sta 1 "Press" 0 "Release";
VAL_ 826 SWC_Up_Sta 1 "Press" 0 "Release";
VAL_ 826 SWC_Trip_Sta 1 "Press" 0 "Release";
VAL_ 826 SWC_Set_down_Sta 1 "Press" 0 "Release";
VAL_ 826 SWC_Right_Sta 1 "Press" 0 "Release";
VAL_ 826 SWC_RegenDown 1 "Press" 0 "Release";
VAL_ 826 SWC_Res_Up_Sta 1 "Press" 0 "Release";
VAL_ 826 SWC_resp_error 1 "Error" 0 "Normal";
VAL_ 826 SWC_mode_Sta 1 "Press" 0 "Release";
VAL_ 826 SWC_Left_Sta 1 "Press" 0 "Release";
VAL_ 826 SWC_RegenUp 1 "Press" 0 "Release";
VAL_ 826 SWC_Down_Sta 1 "Press" 0 "Release";
VAL_ 826 SWC_Distance_Sta 1 "Press" 0 "Release";
VAL_ 826 SWC_A_Resp_Err 1 "Error" 0 "Normal";
VAL_ 826 SWC_ACC_Sta 1 "Press" 0 "Release";
VAL_ 826 SWC_CANCEL_Sta 1 "Press" 0 "Release";
VAL_ 826 SWC_Drivemode_Sta 1 "Press" 0 "Release";
VAL_ 851 L_RLD_Wdw_Running_Sts 7 "Reserved" 5 "Reserved" 4 "Auto Down" 3 "Auto Up" 2 "Manual Down" 1 "Manual Up" 0 "Window stop";
VAL_ 851 L_RLD_Wdw_LocalSwitch 7 "Error" 6 "Reserved" 5 "Reserved" 4 "Auto Down" 3 "Auto Up" 2 "Manual Down" 1 "Manual Up" 0 "Inactive";
VAL_ 851 L_RLD_Wdw_PositionSts 3 "Invalid" 2 "Complete Close" 1 "Complete Open" 0 "Middle position";
VAL_ 851 L_RLD_Val_Wdw_Opened 127 "Invalid";
VAL_ 851 L_RLD_Motor_Ripple_Error 1 "Error" 0 "Normal";
VAL_ 851 L_RLD_Motor_Relay_Error 1 "Error" 0 "Normal";
VAL_ 851 L_RLD_OverHeat_Protect 1 "Active" 0 "Inactive";
VAL_ 851 L_RLD_Wdw_Init 1 "Window init complete" 0 "Window init incomplete";
VAL_ 851 L_RLD_Wdw_OD_Sts 1 "In Anti-pinch status" 0 "Non anti-pinch status";
VAL_ 851 L_RLD_Wdw_Obs_InhibitSts 1 "Obs Inhibit status" 0 "Not Obs Inhibit status";
VAL_ 851 RAPWL_01_LIN_Response_Error 1 "Error" 0 "Normal";
VAL_ 851 L_RRD_Wdw_Running_Sts 7 "Reserved" 5 "Reserved" 4 "Auto Down" 3 "Auto Up" 2 "Manual Down" 1 "Manual Up" 0 "Window stop";
VAL_ 851 L_RRD_Wdw_LocalSwitch 7 "Error" 6 "Reserved" 5 "Reserved" 4 "Auto Down" 3 "Auto Up" 2 "Manual Down" 1 "Manual Up" 0 "Inactive";
VAL_ 851 L_RRD_Wdw_PositionSts 3 "Invalid" 2 "Complete Close" 1 "Complete Open" 0 "Middle position";
VAL_ 851 L_RRD_Val_Wdw_Opened 127 "Invalid";
VAL_ 851 L_RRD_Motor_Ripple_Error 1 "Error" 0 "Normal";
VAL_ 851 L_RRD_Motor_Relay_Error 1 "Error" 0 "Normal";
VAL_ 851 L_RRD_OverHeat_Protect 1 "Active" 0 "Inactive";
VAL_ 851 L_RRD_Wdw_Init 1 "Window init complete" 0 "Window init incomplete";
VAL_ 851 L_RRD_Wdw_OD_Sts 1 "In Anti-pinch status" 0 "Non anti-pinch status";
VAL_ 851 L_RRD_Wdw_Obs_InhibitSts 1 "Obs Inhibit status" 0 "Not Obs Inhibit status";
VAL_ 851 PTG_Inner_SW_2 3 "Stuck" 2 "Press&Hold" 1 "Push" 0 "Off";
VAL_ 854 L_Drv_Wdw_Running_Sts 7 "Reserved" 5 "Reserved" 4 "Auto Down" 3 "Auto Up" 2 "Manual Down" 1 "Manual Up" 0 "Window stop";
VAL_ 854 L_Drv_Wdw_LocalSwitch 7 "Error" 6 "Reserved" 5 "Reserved" 4 "Auto Down" 3 "Auto Up" 2 "Manual Down" 1 "Manual Up" 0 "Inactive";
VAL_ 854 L_Drv_Wdw_PositionSts 3 "Invalid" 2 "Complete Close" 1 "Complete Open" 0 "Middle position";
VAL_ 854 L_Drv_Val_Wdw_Opened 127 "Invalid";
VAL_ 854 L_Drv_Motor_Ripple_Error 1 "Error" 0 "Normal";
VAL_ 854 L_Drv_Motor_Relay_Error 1 "Error" 0 "Normal";
VAL_ 854 L_Drv_OverHeat_Protect 1 "Active" 0 "Inactive";
VAL_ 854 L_Drv_Wdw_Init 1 "Window init complete" 0 "Window init incomplete";
VAL_ 854 L_Drv_Wdw_OD_Sts 1 "In Anti-pinch status" 0 "Non anti-pinch status";
VAL_ 854 L_Drv_Wdw_Obs_InhibitSts 1 "Obs Inhibit status" 0 "Not Obs Inhibit status";
VAL_ 854 FAPWL_01_LIN_Response_Error 1 "Error" 0 "Normal";
VAL_ 854 L_Power_Status 3 "??>16V" 2 "??<9V" 1 "9V????16V" 0 "Default";
VAL_ 854 L_Pas_Wdw_Running_Sts 7 "Reserved" 5 "Reserved" 4 "Auto Down" 3 "Auto Up" 2 "Manual Down" 1 "Manual Up" 0 "Window stop";
VAL_ 854 L_Pas_Wdw_LocalSwitch 7 "Error" 6 "Reserved" 5 "Reserved" 4 "Auto Down" 3 "Auto Up" 2 "Manual Down" 1 "Manual Up" 0 "Inactive";
VAL_ 854 L_Pas_Wdw_PositionSts 3 "Invalid" 2 "Complete Close" 1 "Complete Open" 0 "Middle position";
VAL_ 854 L_Pas_Val_Wdw_Opened 127 "Invalid";
VAL_ 854 L_Pas_Motor_Ripple_Error 1 "Error" 0 "Normal";
VAL_ 854 L_Pas_Motor_Relay_Error 1 "Error" 0 "Normal";
VAL_ 854 L_Pas_OverHeat_Protect 1 "Active" 0 "Inactive";
VAL_ 854 L_Pas_Wdw_Init 1 "Window init complete" 0 "Window init incomplete";
VAL_ 854 L_Pas_Wdw_OD_Sts 1 "In Anti-pinch status" 0 "Non anti-pinch status";
VAL_ 854 L_Pas_Wdw_Obs_InhibitSts 1 "Obs Inhibit status" 0 "Not Obs Inhibit status";
VAL_ 854 L_Drv_Wdw_Pas_Switch 7 "Error" 6 "Reserved" 5 "Reserved" 4 "Auto Down" 3 "Auto Up" 2 "Manual Down" 1 "Manual Up" 0 "Inactive";
VAL_ 854 L_Drv_Wdw_RLD_Switch 7 "Error" 6 "Reserved" 5 "Reserved" 4 "Auto Down" 3 "Auto Up" 2 "Manual Down" 1 "Manual Up" 0 "Inactive";
VAL_ 854 L_Drv_Wdw_RRD_Switch 7 "Error" 6 "Reserved" 5 "Reserved" 4 "Auto Down" 3 "Auto Up" 2 "Manual Down" 1 "Manual Up" 0 "Inactive";
VAL_ 854 L_APM_IntellectClose 1 "Intelligent Close" 0 "No action";
